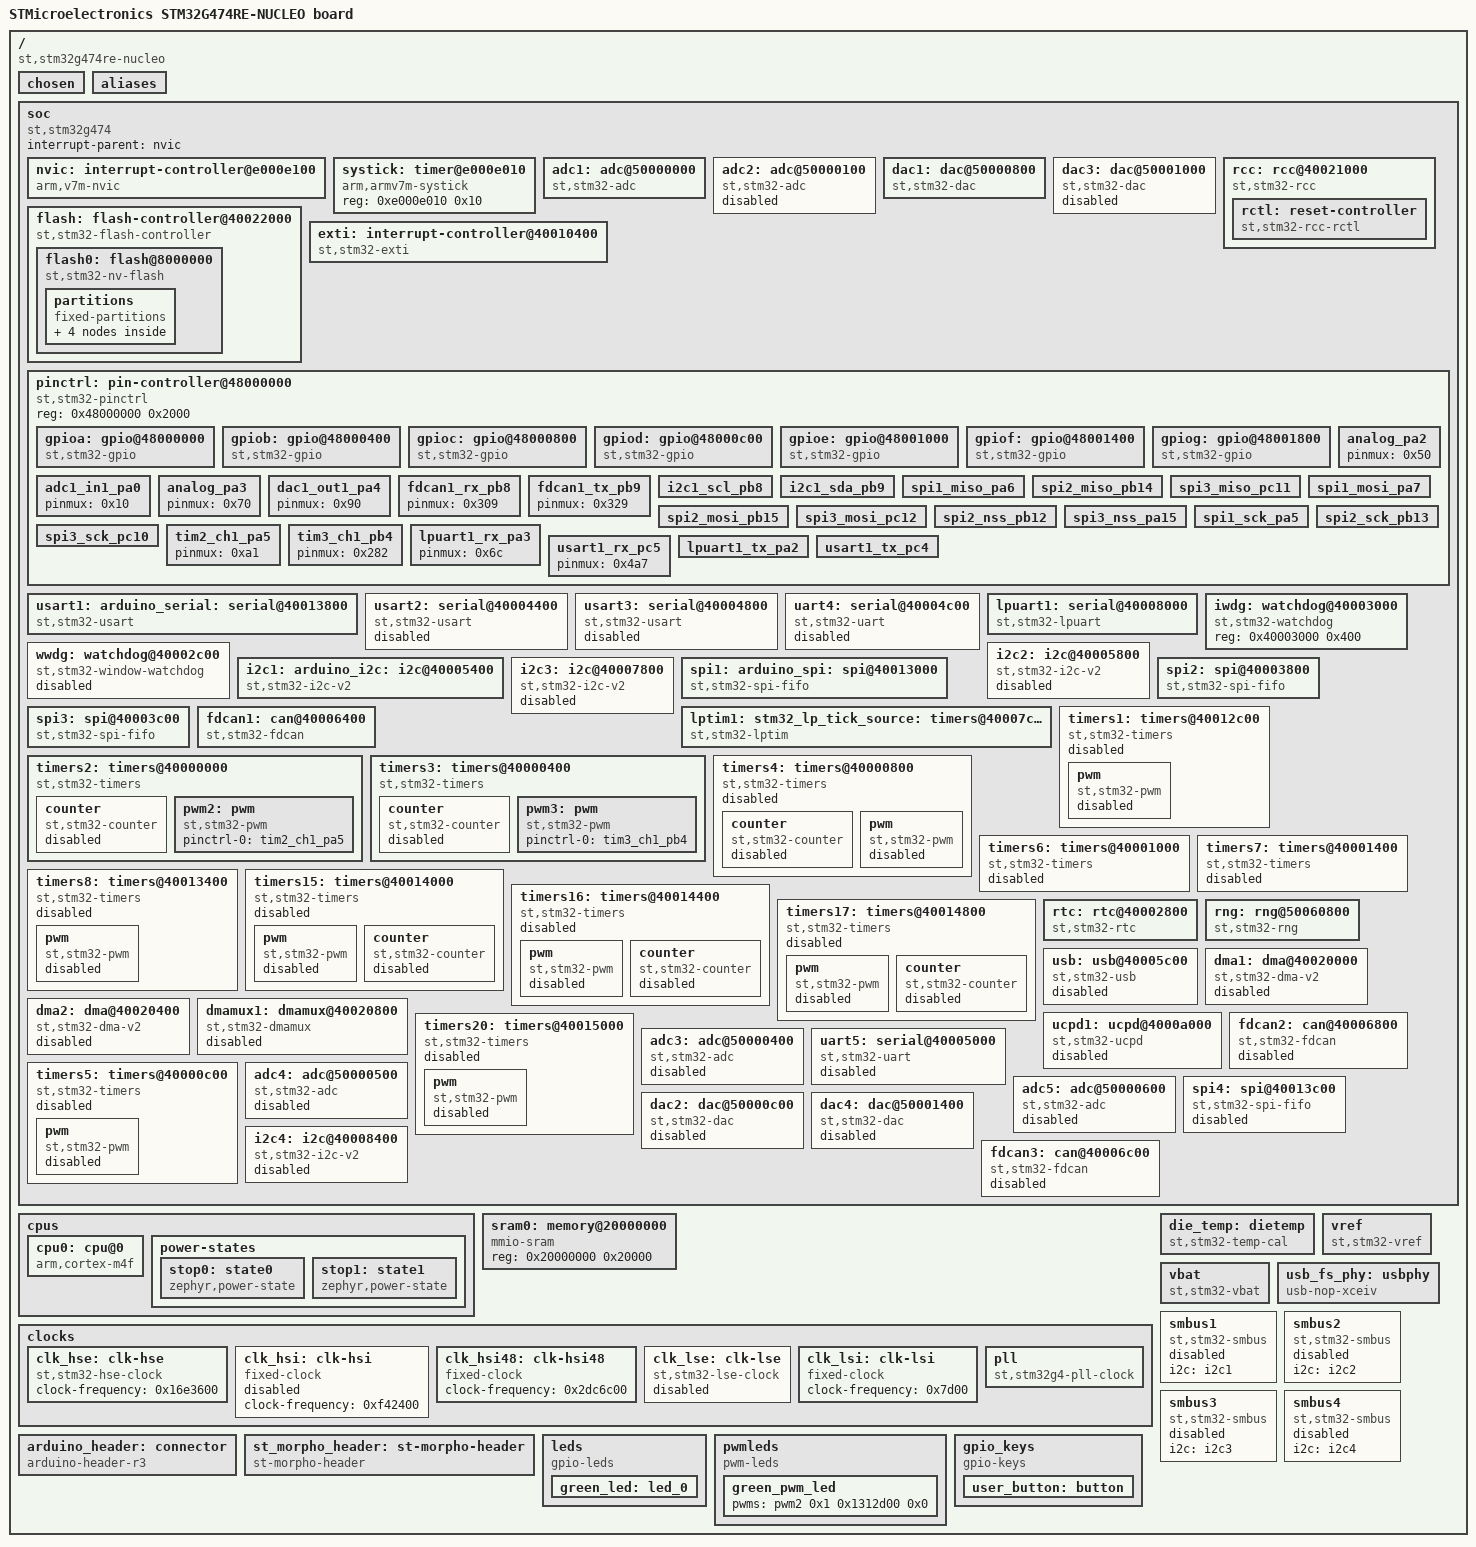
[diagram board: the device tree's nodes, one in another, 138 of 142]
/dts-v1/;

/* node '/' defined in zephyr/dts/common/skeleton.dtsi:9 */
/ {
	#address-cells = < 0x1 >;                              /* in zephyr/dts/common/skeleton.dtsi:10 */
	#size-cells = < 0x1 >;                                 /* in zephyr/dts/common/skeleton.dtsi:11 */
	model = "STMicroelectronics STM32G474RE-NUCLEO board"; /* in zephyr/boards/st/nucleo_g474re/nucleo_g474re.dts:15 */
	compatible = "st,stm32g474re-nucleo";                  /* in zephyr/boards/st/nucleo_g474re/nucleo_g474re.dts:16 */

	/* node '/chosen' defined in zephyr/dts/common/skeleton.dtsi:12 */
	chosen {
		zephyr,entropy = &rng;                    /* in zephyr/dts/arm/st/g4/stm32g4.dtsi:24 */
		zephyr,flash-controller = &flash;         /* in zephyr/dts/arm/st/g4/stm32g4.dtsi:25 */
		zephyr,console = &lpuart1;                /* in zephyr/boards/st/nucleo_g474re/nucleo_g474re.dts:19 */
		zephyr,shell-uart = &lpuart1;             /* in zephyr/boards/st/nucleo_g474re/nucleo_g474re.dts:20 */
		zephyr,sram = &sram0;                     /* in zephyr/boards/st/nucleo_g474re/nucleo_g474re.dts:21 */
		zephyr,flash = &flash0;                   /* in zephyr/boards/st/nucleo_g474re/nucleo_g474re.dts:22 */
		zephyr,code-partition = &slot0_partition; /* in zephyr/boards/st/nucleo_g474re/nucleo_g474re.dts:24 */
		zephyr,canbus = &fdcan1;                  /* in ecu-edge-ai-can-anomaly/firmware/ecu_engine/nucleo_g474re.overlay:19 */
	};

	/* node '/aliases' defined in zephyr/dts/common/skeleton.dtsi:13 */
	aliases {
		led0 = &green_led;         /* in zephyr/boards/st/nucleo_g474re/nucleo_g474re.dts:55 */
		mcuboot-led0 = &green_led; /* in zephyr/boards/st/nucleo_g474re/nucleo_g474re.dts:56 */
		pwm-led0 = &green_pwm_led; /* in zephyr/boards/st/nucleo_g474re/nucleo_g474re.dts:57 */
		sw0 = &user_button;        /* in zephyr/boards/st/nucleo_g474re/nucleo_g474re.dts:58 */
		watchdog0 = &iwdg;         /* in zephyr/boards/st/nucleo_g474re/nucleo_g474re.dts:59 */
		die-temp0 = &die_temp;     /* in zephyr/boards/st/nucleo_g474re/nucleo_g474re.dts:60 */
		volt-sensor0 = &vref;      /* in zephyr/boards/st/nucleo_g474re/nucleo_g474re.dts:61 */
		volt-sensor1 = &vbat;      /* in zephyr/boards/st/nucleo_g474re/nucleo_g474re.dts:62 */
	};

	/* node '/soc' defined in zephyr/dts/arm/armv7-m.dtsi:6 */
	soc {
		#address-cells = < 0x1 >;     /* in zephyr/dts/arm/armv7-m.dtsi:7 */
		#size-cells = < 0x1 >;        /* in zephyr/dts/arm/armv7-m.dtsi:8 */
		interrupt-parent = < &nvic >; /* in zephyr/dts/arm/armv7-m.dtsi:10 */
		ranges;                       /* in zephyr/dts/arm/armv7-m.dtsi:11 */
		compatible = "st,stm32g474",
		             "st,stm32g4",
		             "simple-bus";    /* in zephyr/dts/arm/st/g4/stm32g474.dtsi:11 */

		/* node '/soc/interrupt-controller@e000e100' defined in zephyr/dts/arm/armv7-m.dtsi:13 */
		nvic: interrupt-controller@e000e100 {
			#address-cells = < 0x1 >;            /* in zephyr/dts/arm/armv7-m.dtsi:14 */
			compatible = "arm,v7m-nvic";         /* in zephyr/dts/arm/armv7-m.dtsi:15 */
			reg = < 0xe000e100 0xc00 >;          /* in zephyr/dts/arm/armv7-m.dtsi:16 */
			interrupt-controller;                /* in zephyr/dts/arm/armv7-m.dtsi:17 */
			#interrupt-cells = < 0x2 >;          /* in zephyr/dts/arm/armv7-m.dtsi:18 */
			arm,num-irq-priority-bits = < 0x4 >; /* in zephyr/dts/arm/st/g4/stm32g4.dtsi:726 */
			phandle = < 0x1 >;                   /* in zephyr/dts/arm/armv7-m.dtsi:10 */
		};

		/* node '/soc/timer@e000e010' defined in zephyr/dts/arm/armv7-m.dtsi:21 */
		systick: timer@e000e010 {
			compatible = "arm,armv7m-systick"; /* in zephyr/dts/arm/armv7-m.dtsi:22 */
			reg = < 0xe000e010 0x10 >;         /* in zephyr/dts/arm/armv7-m.dtsi:23 */
		};

		/* node '/soc/adc@50000000' defined in zephyr/dts/arm/st/g4/stm32g4.dtsi:106 */
		adc1: adc@50000000 {
			compatible = "st,stm32-adc";                                /* in zephyr/dts/arm/st/g4/stm32g4.dtsi:107 */
			reg = < 0x50000000 0x100 >;                                 /* in zephyr/dts/arm/st/g4/stm32g4.dtsi:108 */
			clocks = < &rcc 0x4c 0x2000 >;                              /* in zephyr/dts/arm/st/g4/stm32g4.dtsi:109 */
			interrupts = < 0x12 0x0 >;                                  /* in zephyr/dts/arm/st/g4/stm32g4.dtsi:110 */
			#io-channel-cells = < 0x1 >;                                /* in zephyr/dts/arm/st/g4/stm32g4.dtsi:112 */
			resolutions = < 0x60630c 0x51630c 0x42630c 0x33630c >;      /* in zephyr/dts/arm/st/g4/stm32g4.dtsi:113 */
			sampling-times = < 0x3 0x7 0xd 0x19 0x30 0x5d 0xf8 0x281 >; /* in zephyr/dts/arm/st/g4/stm32g4.dtsi:117 */
			st,adc-sequencer = "FULLY_CONFIGURABLE";                    /* in zephyr/dts/arm/st/g4/stm32g4.dtsi:118 */
			st,adc-oversampler = "OVERSAMPLER_MINIMAL";                 /* in zephyr/dts/arm/st/g4/stm32g4.dtsi:119 */
			pinctrl-0 = < &adc1_in1_pa0 >;                              /* in zephyr/boards/st/nucleo_g474re/nucleo_g474re.dts:210 */
			pinctrl-names = "default";                                  /* in zephyr/boards/st/nucleo_g474re/nucleo_g474re.dts:211 */
			st,adc-clock-source = "SYNC";                               /* in zephyr/boards/st/nucleo_g474re/nucleo_g474re.dts:212 */
			st,adc-prescaler = < 0x4 >;                                 /* in zephyr/boards/st/nucleo_g474re/nucleo_g474re.dts:213 */
			status = "okay";                                            /* in zephyr/boards/st/nucleo_g474re/nucleo_g474re.dts:214 */
			phandle = < 0x23 >;                                         /* in zephyr/dts/arm/st/g4/stm32g4.dtsi:676 */
		};

		/* node '/soc/adc@50000100' defined in zephyr/dts/arm/st/g4/stm32g4.dtsi:122 */
		adc2: adc@50000100 {
			compatible = "st,stm32-adc";                                /* in zephyr/dts/arm/st/g4/stm32g4.dtsi:123 */
			reg = < 0x50000100 0x100 >;                                 /* in zephyr/dts/arm/st/g4/stm32g4.dtsi:124 */
			clocks = < &rcc 0x4c 0x2000 >;                              /* in zephyr/dts/arm/st/g4/stm32g4.dtsi:125 */
			interrupts = < 0x12 0x0 >;                                  /* in zephyr/dts/arm/st/g4/stm32g4.dtsi:126 */
			status = "disabled";                                        /* in zephyr/dts/arm/st/g4/stm32g4.dtsi:127 */
			#io-channel-cells = < 0x1 >;                                /* in zephyr/dts/arm/st/g4/stm32g4.dtsi:128 */
			resolutions = < 0x60630c 0x51630c 0x42630c 0x33630c >;      /* in zephyr/dts/arm/st/g4/stm32g4.dtsi:129 */
			sampling-times = < 0x3 0x7 0xd 0x19 0x30 0x5d 0xf8 0x281 >; /* in zephyr/dts/arm/st/g4/stm32g4.dtsi:133 */
			st,adc-sequencer = "FULLY_CONFIGURABLE";                    /* in zephyr/dts/arm/st/g4/stm32g4.dtsi:134 */
			st,adc-oversampler = "OVERSAMPLER_MINIMAL";                 /* in zephyr/dts/arm/st/g4/stm32g4.dtsi:135 */
		};

		/* node '/soc/dac@50000800' defined in zephyr/dts/arm/st/g4/stm32g4.dtsi:138 */
		dac1: dac@50000800 {
			compatible = "st,stm32-dac";    /* in zephyr/dts/arm/st/g4/stm32g4.dtsi:139 */
			reg = < 0x50000800 0x400 >;     /* in zephyr/dts/arm/st/g4/stm32g4.dtsi:140 */
			clocks = < &rcc 0x4c 0x10000 >; /* in zephyr/dts/arm/st/g4/stm32g4.dtsi:141 */
			#io-channel-cells = < 0x1 >;    /* in zephyr/dts/arm/st/g4/stm32g4.dtsi:143 */
			pinctrl-0 = < &dac1_out1_pa4 >; /* in zephyr/boards/st/nucleo_g474re/nucleo_g474re.dts:222 */
			pinctrl-names = "default";      /* in zephyr/boards/st/nucleo_g474re/nucleo_g474re.dts:223 */
			status = "okay";                /* in zephyr/boards/st/nucleo_g474re/nucleo_g474re.dts:224 */
		};

		/* node '/soc/dac@50001000' defined in zephyr/dts/arm/st/g4/stm32g4.dtsi:146 */
		dac3: dac@50001000 {
			compatible = "st,stm32-dac";    /* in zephyr/dts/arm/st/g4/stm32g4.dtsi:147 */
			reg = < 0x50001000 0x400 >;     /* in zephyr/dts/arm/st/g4/stm32g4.dtsi:148 */
			clocks = < &rcc 0x4c 0x40000 >; /* in zephyr/dts/arm/st/g4/stm32g4.dtsi:149 */
			status = "disabled";            /* in zephyr/dts/arm/st/g4/stm32g4.dtsi:150 */
			#io-channel-cells = < 0x1 >;    /* in zephyr/dts/arm/st/g4/stm32g4.dtsi:151 */
		};

		/* node '/soc/flash-controller@40022000' defined in zephyr/dts/arm/st/g4/stm32g4.dtsi:154 */
		flash: flash-controller@40022000 {
			compatible = "st,stm32-flash-controller",
			             "st,stm32g4-flash-controller"; /* in zephyr/dts/arm/st/g4/stm32g4.dtsi:155 */
			reg = < 0x40022000 0x400 >;                 /* in zephyr/dts/arm/st/g4/stm32g4.dtsi:156 */
			interrupts = < 0x3 0x0 >;                   /* in zephyr/dts/arm/st/g4/stm32g4.dtsi:157 */
			clocks = < &rcc 0x48 0x100 >;               /* in zephyr/dts/arm/st/g4/stm32g4.dtsi:158 */
			#address-cells = < 0x1 >;                   /* in zephyr/dts/arm/st/g4/stm32g4.dtsi:160 */
			#size-cells = < 0x1 >;                      /* in zephyr/dts/arm/st/g4/stm32g4.dtsi:161 */

			/* node '/soc/flash-controller@40022000/flash@8000000' defined in zephyr/dts/arm/st/g4/stm32g4.dtsi:163 */
			flash0: flash@8000000 {
				compatible = "st,stm32-nv-flash",
				             "soc-nv-flash";      /* in zephyr/dts/arm/st/g4/stm32g4.dtsi:164 */
				write-block-size = < 0x8 >;       /* in zephyr/dts/arm/st/g4/stm32g4.dtsi:166 */
				erase-block-size = < 0x800 >;     /* in zephyr/dts/arm/st/g4/stm32g4.dtsi:167 */
				max-erase-time = < 0x19 >;        /* in zephyr/dts/arm/st/g4/stm32g4.dtsi:169 */
				reg = < 0x8000000 0x80000 >;      /* in zephyr/dts/arm/st/g4/stm32g474Xe.dtsi:15 */

				/* node '/soc/flash-controller@40022000/flash@8000000/partitions' defined in zephyr/boards/st/nucleo_g474re/nucleo_g474re.dts:173 */
				partitions {
					compatible = "fixed-partitions"; /* in zephyr/boards/st/nucleo_g474re/nucleo_g474re.dts:174 */
					#address-cells = < 0x1 >;        /* in zephyr/boards/st/nucleo_g474re/nucleo_g474re.dts:175 */
					#size-cells = < 0x1 >;           /* in zephyr/boards/st/nucleo_g474re/nucleo_g474re.dts:176 */

					/* node '/soc/flash-controller@40022000/flash@8000000/partitions/partition@0' defined in zephyr/boards/st/nucleo_g474re/nucleo_g474re.dts:178 */
					boot_partition: partition@0 {
						label = "mcuboot";    /* in zephyr/boards/st/nucleo_g474re/nucleo_g474re.dts:179 */
						reg = < 0x0 0x8800 >; /* in zephyr/boards/st/nucleo_g474re/nucleo_g474re.dts:180 */
					};

					/* node '/soc/flash-controller@40022000/flash@8000000/partitions/partition@8800' defined in zephyr/boards/st/nucleo_g474re/nucleo_g474re.dts:183 */
					slot0_partition: partition@8800 {
						label = "image-0";        /* in zephyr/boards/st/nucleo_g474re/nucleo_g474re.dts:184 */
						reg = < 0x8800 0x3c000 >; /* in zephyr/boards/st/nucleo_g474re/nucleo_g474re.dts:185 */
					};

					/* node '/soc/flash-controller@40022000/flash@8000000/partitions/partition@44800' defined in zephyr/boards/st/nucleo_g474re/nucleo_g474re.dts:188 */
					slot1_partition: partition@44800 {
						label = "image-1";         /* in zephyr/boards/st/nucleo_g474re/nucleo_g474re.dts:189 */
						reg = < 0x44800 0x3a800 >; /* in zephyr/boards/st/nucleo_g474re/nucleo_g474re.dts:190 */
					};

					/* node '/soc/flash-controller@40022000/flash@8000000/partitions/partition@7f000' defined in zephyr/boards/st/nucleo_g474re/nucleo_g474re.dts:194 */
					storage_partition: partition@7f000 {
						label = "storage";        /* in zephyr/boards/st/nucleo_g474re/nucleo_g474re.dts:195 */
						reg = < 0x7f000 0x1000 >; /* in zephyr/boards/st/nucleo_g474re/nucleo_g474re.dts:196 */
					};
				};
			};
		};

		/* node '/soc/rcc@40021000' defined in zephyr/dts/arm/st/g4/stm32g4.dtsi:173 */
		rcc: rcc@40021000 {
			compatible = "st,stm32-rcc";     /* in zephyr/dts/arm/st/g4/stm32g4.dtsi:174 */
			#clock-cells = < 0x2 >;          /* in zephyr/dts/arm/st/g4/stm32g4.dtsi:175 */
			reg = < 0x40021000 0x400 >;      /* in zephyr/dts/arm/st/g4/stm32g4.dtsi:176 */
			undershoot-prevention;           /* in zephyr/dts/arm/st/g4/stm32g4.dtsi:177 */
			clocks = < &pll >;               /* in zephyr/boards/st/nucleo_g474re/nucleo_g474re.dts:90 */
			clock-frequency = < 0xa21fe80 >; /* in zephyr/boards/st/nucleo_g474re/nucleo_g474re.dts:91 */
			ahb-prescaler = < 0x1 >;         /* in zephyr/boards/st/nucleo_g474re/nucleo_g474re.dts:92 */
			apb1-prescaler = < 0x1 >;        /* in zephyr/boards/st/nucleo_g474re/nucleo_g474re.dts:93 */
			apb2-prescaler = < 0x1 >;        /* in zephyr/boards/st/nucleo_g474re/nucleo_g474re.dts:94 */
			phandle = < 0x2 >;               /* in zephyr/dts/arm/st/g4/stm32g4.dtsi:109 */

			/* node '/soc/rcc@40021000/reset-controller' defined in zephyr/dts/arm/st/g4/stm32g4.dtsi:179 */
			rctl: reset-controller {
				compatible = "st,stm32-rcc-rctl"; /* in zephyr/dts/arm/st/g4/stm32g4.dtsi:180 */
				#reset-cells = < 0x1 >;           /* in zephyr/dts/arm/st/g4/stm32g4.dtsi:181 */
				phandle = < 0x6 >;                /* in zephyr/dts/arm/st/g4/stm32g4.dtsi:268 */
			};
		};

		/* node '/soc/interrupt-controller@40010400' defined in zephyr/dts/arm/st/g4/stm32g4.dtsi:185 */
		exti: interrupt-controller@40010400 {
			compatible = "st,stm32-exti";  /* in zephyr/dts/arm/st/g4/stm32g4.dtsi:186 */
			interrupt-controller;          /* in zephyr/dts/arm/st/g4/stm32g4.dtsi:187 */
			#interrupt-cells = < 0x1 >;    /* in zephyr/dts/arm/st/g4/stm32g4.dtsi:188 */
			#address-cells = < 0x1 >;      /* in zephyr/dts/arm/st/g4/stm32g4.dtsi:189 */
			reg = < 0x40010400 0x400 >;    /* in zephyr/dts/arm/st/g4/stm32g4.dtsi:190 */
			clocks = < &rcc 0x60 0x1 >;    /* in zephyr/dts/arm/st/g4/stm32g4.dtsi:191 */
			num-lines = < 0x40 >;          /* in zephyr/dts/arm/st/g4/stm32g4.dtsi:192 */
			interrupts = < 0x6 0x0 >,
			             < 0x7 0x0 >,
			             < 0x8 0x0 >,
			             < 0x9 0x0 >,
			             < 0xa 0x0 >,
			             < 0x17 0x0 >,
			             < 0x28 0x0 >;     /* in zephyr/dts/arm/st/g4/stm32g4.dtsi:193 */
			interrupt-names = "line0",
			                  "line1",
			                  "line2-TSC",
			                  "line3",
			                  "line4",
			                  "line5-9",
			                  "line10-15"; /* in zephyr/dts/arm/st/g4/stm32g4.dtsi:195 */
			line-ranges = < 0x0 0x1 >,
			              < 0x1 0x1 >,
			              < 0x2 0x1 >,
			              < 0x3 0x1 >,
			              < 0x4 0x1 >,
			              < 0x5 0x5 >,
			              < 0xa 0x6 >;     /* in zephyr/dts/arm/st/g4/stm32g4.dtsi:197 */
		};

		/* node '/soc/pin-controller@48000000' defined in zephyr/dts/arm/st/g4/stm32g4.dtsi:201 */
		pinctrl: pin-controller@48000000 {
			compatible = "st,stm32-pinctrl"; /* in zephyr/dts/arm/st/g4/stm32g4.dtsi:202 */
			#address-cells = < 0x1 >;        /* in zephyr/dts/arm/st/g4/stm32g4.dtsi:203 */
			#size-cells = < 0x1 >;           /* in zephyr/dts/arm/st/g4/stm32g4.dtsi:204 */
			reg = < 0x48000000 0x2000 >;     /* in zephyr/dts/arm/st/g4/stm32g4.dtsi:205 */

			/* node '/soc/pin-controller@48000000/gpio@48000000' defined in zephyr/dts/arm/st/g4/stm32g4.dtsi:207 */
			gpioa: gpio@48000000 {
				compatible = "st,stm32-gpio"; /* in zephyr/dts/arm/st/g4/stm32g4.dtsi:208 */
				gpio-controller;              /* in zephyr/dts/arm/st/g4/stm32g4.dtsi:209 */
				#gpio-cells = < 0x2 >;        /* in zephyr/dts/arm/st/g4/stm32g4.dtsi:210 */
				reg = < 0x48000000 0x400 >;   /* in zephyr/dts/arm/st/g4/stm32g4.dtsi:211 */
				clocks = < &rcc 0x4c 0x1 >;   /* in zephyr/dts/arm/st/g4/stm32g4.dtsi:212 */
				phandle = < 0x28 >;           /* in zephyr/boards/st/nucleo_g474re/arduino_r3_connector.dtsi:13 */
			};

			/* node '/soc/pin-controller@48000000/gpio@48000400' defined in zephyr/dts/arm/st/g4/stm32g4.dtsi:215 */
			gpiob: gpio@48000400 {
				compatible = "st,stm32-gpio"; /* in zephyr/dts/arm/st/g4/stm32g4.dtsi:216 */
				gpio-controller;              /* in zephyr/dts/arm/st/g4/stm32g4.dtsi:217 */
				#gpio-cells = < 0x2 >;        /* in zephyr/dts/arm/st/g4/stm32g4.dtsi:218 */
				reg = < 0x48000400 0x400 >;   /* in zephyr/dts/arm/st/g4/stm32g4.dtsi:219 */
				clocks = < &rcc 0x4c 0x2 >;   /* in zephyr/dts/arm/st/g4/stm32g4.dtsi:220 */
				phandle = < 0x12 >;           /* in zephyr/boards/st/nucleo_g474re/nucleo_g474re.dts:121 */
			};

			/* node '/soc/pin-controller@48000000/gpio@48000800' defined in zephyr/dts/arm/st/g4/stm32g4.dtsi:223 */
			gpioc: gpio@48000800 {
				compatible = "st,stm32-gpio"; /* in zephyr/dts/arm/st/g4/stm32g4.dtsi:224 */
				gpio-controller;              /* in zephyr/dts/arm/st/g4/stm32g4.dtsi:225 */
				#gpio-cells = < 0x2 >;        /* in zephyr/dts/arm/st/g4/stm32g4.dtsi:226 */
				reg = < 0x48000800 0x400 >;   /* in zephyr/dts/arm/st/g4/stm32g4.dtsi:227 */
				clocks = < &rcc 0x4c 0x4 >;   /* in zephyr/dts/arm/st/g4/stm32g4.dtsi:228 */
				phandle = < 0x29 >;           /* in zephyr/boards/st/nucleo_g474re/arduino_r3_connector.dtsi:13 */
			};

			/* node '/soc/pin-controller@48000000/gpio@48000c00' defined in zephyr/dts/arm/st/g4/stm32g4.dtsi:231 */
			gpiod: gpio@48000c00 {
				compatible = "st,stm32-gpio"; /* in zephyr/dts/arm/st/g4/stm32g4.dtsi:232 */
				gpio-controller;              /* in zephyr/dts/arm/st/g4/stm32g4.dtsi:233 */
				#gpio-cells = < 0x2 >;        /* in zephyr/dts/arm/st/g4/stm32g4.dtsi:234 */
				reg = < 0x48000c00 0x400 >;   /* in zephyr/dts/arm/st/g4/stm32g4.dtsi:235 */
				clocks = < &rcc 0x4c 0x8 >;   /* in zephyr/dts/arm/st/g4/stm32g4.dtsi:236 */
				phandle = < 0x2a >;           /* in zephyr/boards/st/nucleo_g474re/st_morpho_connector.dtsi:15 */
			};

			/* node '/soc/pin-controller@48000000/gpio@48001000' defined in zephyr/dts/arm/st/g4/stm32g4.dtsi:239 */
			gpioe: gpio@48001000 {
				compatible = "st,stm32-gpio"; /* in zephyr/dts/arm/st/g4/stm32g4.dtsi:240 */
				gpio-controller;              /* in zephyr/dts/arm/st/g4/stm32g4.dtsi:241 */
				#gpio-cells = < 0x2 >;        /* in zephyr/dts/arm/st/g4/stm32g4.dtsi:242 */
				reg = < 0x48001000 0x400 >;   /* in zephyr/dts/arm/st/g4/stm32g4.dtsi:243 */
				clocks = < &rcc 0x4c 0x10 >;  /* in zephyr/dts/arm/st/g4/stm32g4.dtsi:244 */
			};

			/* node '/soc/pin-controller@48000000/gpio@48001400' defined in zephyr/dts/arm/st/g4/stm32g4.dtsi:247 */
			gpiof: gpio@48001400 {
				compatible = "st,stm32-gpio"; /* in zephyr/dts/arm/st/g4/stm32g4.dtsi:248 */
				gpio-controller;              /* in zephyr/dts/arm/st/g4/stm32g4.dtsi:249 */
				#gpio-cells = < 0x2 >;        /* in zephyr/dts/arm/st/g4/stm32g4.dtsi:250 */
				reg = < 0x48001400 0x400 >;   /* in zephyr/dts/arm/st/g4/stm32g4.dtsi:251 */
				clocks = < &rcc 0x4c 0x20 >;  /* in zephyr/dts/arm/st/g4/stm32g4.dtsi:252 */
				phandle = < 0x2b >;           /* in zephyr/boards/st/nucleo_g474re/st_morpho_connector.dtsi:15 */
			};

			/* node '/soc/pin-controller@48000000/gpio@48001800' defined in zephyr/dts/arm/st/g4/stm32g4.dtsi:255 */
			gpiog: gpio@48001800 {
				compatible = "st,stm32-gpio"; /* in zephyr/dts/arm/st/g4/stm32g4.dtsi:256 */
				gpio-controller;              /* in zephyr/dts/arm/st/g4/stm32g4.dtsi:257 */
				#gpio-cells = < 0x2 >;        /* in zephyr/dts/arm/st/g4/stm32g4.dtsi:258 */
				reg = < 0x48001800 0x400 >;   /* in zephyr/dts/arm/st/g4/stm32g4.dtsi:259 */
				clocks = < &rcc 0x4c 0x40 >;  /* in zephyr/dts/arm/st/g4/stm32g4.dtsi:260 */
			};

			/* node '/soc/pin-controller@48000000/adc1_in1_pa0' defined in modules/hal/stm32/dts/st/g4/stm32g474r(b-c-e)tx-pinctrl.dtsi:15 */
			adc1_in1_pa0: adc1_in1_pa0 {
				pinmux = < 0x10 >; /* in modules/hal/stm32/dts/st/g4/stm32g474r(b-c-e)tx-pinctrl.dtsi:16 */
				phandle = < 0x3 >; /* in zephyr/boards/st/nucleo_g474re/nucleo_g474re.dts:210 */
			};

			/* node '/soc/pin-controller@48000000/analog_pa2' defined in modules/hal/stm32/dts/st/g4/stm32g474r(b-c-e)tx-pinctrl.dtsi:177 */
			analog_pa2: analog_pa2 {
				pinmux = < 0x50 >; /* in modules/hal/stm32/dts/st/g4/stm32g474r(b-c-e)tx-pinctrl.dtsi:178 */
				phandle = < 0xb >; /* in zephyr/boards/st/nucleo_g474re/nucleo_g474re.dts:106 */
			};

			/* node '/soc/pin-controller@48000000/analog_pa3' defined in modules/hal/stm32/dts/st/g4/stm32g474r(b-c-e)tx-pinctrl.dtsi:181 */
			analog_pa3: analog_pa3 {
				pinmux = < 0x70 >; /* in modules/hal/stm32/dts/st/g4/stm32g474r(b-c-e)tx-pinctrl.dtsi:182 */
				phandle = < 0xc >; /* in zephyr/boards/st/nucleo_g474re/nucleo_g474re.dts:106 */
			};

			/* node '/soc/pin-controller@48000000/dac1_out1_pa4' defined in modules/hal/stm32/dts/st/g4/stm32g474r(b-c-e)tx-pinctrl.dtsi:379 */
			dac1_out1_pa4: dac1_out1_pa4 {
				pinmux = < 0x90 >; /* in modules/hal/stm32/dts/st/g4/stm32g474r(b-c-e)tx-pinctrl.dtsi:380 */
				phandle = < 0x4 >; /* in zephyr/boards/st/nucleo_g474re/nucleo_g474re.dts:222 */
			};

			/* node '/soc/pin-controller@48000000/fdcan1_rx_pb8' defined in modules/hal/stm32/dts/st/g4/stm32g474r(b-c-e)tx-pinctrl.dtsi:397 */
			fdcan1_rx_pb8: fdcan1_rx_pb8 {
				pinmux = < 0x309 >; /* in ecu-edge-ai-can-anomaly/firmware/ecu_engine/nucleo_g474re.overlay:3 */
				phandle = < 0x1b >; /* in ecu-edge-ai-can-anomaly/firmware/ecu_engine/nucleo_g474re.overlay:11 */
			};

			/* node '/soc/pin-controller@48000000/fdcan1_tx_pb9' defined in modules/hal/stm32/dts/st/g4/stm32g474r(b-c-e)tx-pinctrl.dtsi:423 */
			fdcan1_tx_pb9: fdcan1_tx_pb9 {
				pinmux = < 0x329 >; /* in ecu-edge-ai-can-anomaly/firmware/ecu_engine/nucleo_g474re.overlay:6 */
				phandle = < 0x1c >; /* in ecu-edge-ai-can-anomaly/firmware/ecu_engine/nucleo_g474re.overlay:11 */
			};

			/* node '/soc/pin-controller@48000000/i2c1_scl_pb8' defined in modules/hal/stm32/dts/st/g4/stm32g474r(b-c-e)tx-pinctrl.dtsi:571 */
			i2c1_scl_pb8: i2c1_scl_pb8 {
				pinmux = < 0x304 >; /* in modules/hal/stm32/dts/st/g4/stm32g474r(b-c-e)tx-pinctrl.dtsi:572 */
				bias-pull-up;       /* in modules/hal/stm32/dts/st/g4/stm32g474r(b-c-e)tx-pinctrl.dtsi:573 */
				drive-open-drain;   /* in modules/hal/stm32/dts/st/g4/stm32g474r(b-c-e)tx-pinctrl.dtsi:574 */
				phandle = < 0xd >;  /* in zephyr/boards/st/nucleo_g474re/nucleo_g474re.dts:113 */
			};

			/* node '/soc/pin-controller@48000000/i2c1_sda_pb9' defined in modules/hal/stm32/dts/st/g4/stm32g474r(b-c-e)tx-pinctrl.dtsi:627 */
			i2c1_sda_pb9: i2c1_sda_pb9 {
				pinmux = < 0x324 >; /* in modules/hal/stm32/dts/st/g4/stm32g474r(b-c-e)tx-pinctrl.dtsi:628 */
				bias-pull-up;       /* in modules/hal/stm32/dts/st/g4/stm32g474r(b-c-e)tx-pinctrl.dtsi:629 */
				drive-open-drain;   /* in modules/hal/stm32/dts/st/g4/stm32g474r(b-c-e)tx-pinctrl.dtsi:630 */
				phandle = < 0xe >;  /* in zephyr/boards/st/nucleo_g474re/nucleo_g474re.dts:113 */
			};

			/* node '/soc/pin-controller@48000000/spi1_miso_pa6' defined in modules/hal/stm32/dts/st/g4/stm32g474r(b-c-e)tx-pinctrl.dtsi:984 */
			spi1_miso_pa6: spi1_miso_pa6 {
				pinmux = < 0xc5 >;  /* in modules/hal/stm32/dts/st/g4/stm32g474r(b-c-e)tx-pinctrl.dtsi:985 */
				bias-pull-down;     /* in modules/hal/stm32/dts/st/g4/stm32g474r(b-c-e)tx-pinctrl.dtsi:986 */
				phandle = < 0x10 >; /* in zephyr/boards/st/nucleo_g474re/nucleo_g474re.dts:119 */
			};

			/* node '/soc/pin-controller@48000000/spi2_miso_pb14' defined in modules/hal/stm32/dts/st/g4/stm32g474r(b-c-e)tx-pinctrl.dtsi:999 */
			spi2_miso_pb14: spi2_miso_pb14 {
				pinmux = < 0x3c5 >; /* in modules/hal/stm32/dts/st/g4/stm32g474r(b-c-e)tx-pinctrl.dtsi:1000 */
				bias-pull-down;     /* in modules/hal/stm32/dts/st/g4/stm32g474r(b-c-e)tx-pinctrl.dtsi:1001 */
				phandle = < 0x15 >; /* in zephyr/boards/st/nucleo_g474re/nucleo_g474re.dts:126 */
			};

			/* node '/soc/pin-controller@48000000/spi3_miso_pc11' defined in modules/hal/stm32/dts/st/g4/stm32g474r(b-c-e)tx-pinctrl.dtsi:1009 */
			spi3_miso_pc11: spi3_miso_pc11 {
				pinmux = < 0x566 >; /* in modules/hal/stm32/dts/st/g4/stm32g474r(b-c-e)tx-pinctrl.dtsi:1010 */
				bias-pull-down;     /* in modules/hal/stm32/dts/st/g4/stm32g474r(b-c-e)tx-pinctrl.dtsi:1011 */
				phandle = < 0x19 >; /* in zephyr/boards/st/nucleo_g474re/nucleo_g474re.dts:134 */
			};

			/* node '/soc/pin-controller@48000000/spi1_mosi_pa7' defined in modules/hal/stm32/dts/st/g4/stm32g474r(b-c-e)tx-pinctrl.dtsi:1016 */
			spi1_mosi_pa7: spi1_mosi_pa7 {
				pinmux = < 0xe5 >;  /* in modules/hal/stm32/dts/st/g4/stm32g474r(b-c-e)tx-pinctrl.dtsi:1017 */
				bias-pull-down;     /* in modules/hal/stm32/dts/st/g4/stm32g474r(b-c-e)tx-pinctrl.dtsi:1018 */
				phandle = < 0x11 >; /* in zephyr/boards/st/nucleo_g474re/nucleo_g474re.dts:119 */
			};

			/* node '/soc/pin-controller@48000000/spi2_mosi_pb15' defined in modules/hal/stm32/dts/st/g4/stm32g474r(b-c-e)tx-pinctrl.dtsi:1031 */
			spi2_mosi_pb15: spi2_mosi_pb15 {
				pinmux = < 0x3e5 >; /* in modules/hal/stm32/dts/st/g4/stm32g474r(b-c-e)tx-pinctrl.dtsi:1032 */
				bias-pull-down;     /* in modules/hal/stm32/dts/st/g4/stm32g474r(b-c-e)tx-pinctrl.dtsi:1033 */
				phandle = < 0x16 >; /* in zephyr/boards/st/nucleo_g474re/nucleo_g474re.dts:126 */
			};

			/* node '/soc/pin-controller@48000000/spi3_mosi_pc12' defined in modules/hal/stm32/dts/st/g4/stm32g474r(b-c-e)tx-pinctrl.dtsi:1041 */
			spi3_mosi_pc12: spi3_mosi_pc12 {
				pinmux = < 0x586 >; /* in modules/hal/stm32/dts/st/g4/stm32g474r(b-c-e)tx-pinctrl.dtsi:1042 */
				bias-pull-down;     /* in modules/hal/stm32/dts/st/g4/stm32g474r(b-c-e)tx-pinctrl.dtsi:1043 */
				phandle = < 0x1a >; /* in zephyr/boards/st/nucleo_g474re/nucleo_g474re.dts:134 */
			};

			/* node '/soc/pin-controller@48000000/spi2_nss_pb12' defined in modules/hal/stm32/dts/st/g4/stm32g474r(b-c-e)tx-pinctrl.dtsi:1058 */
			spi2_nss_pb12: spi2_nss_pb12 {
				pinmux = < 0x385 >; /* in modules/hal/stm32/dts/st/g4/stm32g474r(b-c-e)tx-pinctrl.dtsi:1059 */
				bias-pull-up;       /* in modules/hal/stm32/dts/st/g4/stm32g474r(b-c-e)tx-pinctrl.dtsi:1060 */
				phandle = < 0x13 >; /* in zephyr/boards/st/nucleo_g474re/nucleo_g474re.dts:126 */
			};

			/* node '/soc/pin-controller@48000000/spi3_nss_pa15' defined in modules/hal/stm32/dts/st/g4/stm32g474r(b-c-e)tx-pinctrl.dtsi:1073 */
			spi3_nss_pa15: spi3_nss_pa15 {
				pinmux = < 0x1e6 >; /* in modules/hal/stm32/dts/st/g4/stm32g474r(b-c-e)tx-pinctrl.dtsi:1074 */
				bias-pull-up;       /* in modules/hal/stm32/dts/st/g4/stm32g474r(b-c-e)tx-pinctrl.dtsi:1075 */
				phandle = < 0x17 >; /* in zephyr/boards/st/nucleo_g474re/nucleo_g474re.dts:134 */
			};

			/* node '/soc/pin-controller@48000000/spi1_sck_pa5' defined in modules/hal/stm32/dts/st/g4/stm32g474r(b-c-e)tx-pinctrl.dtsi:1080 */
			spi1_sck_pa5: spi1_sck_pa5 {
				pinmux = < 0xa5 >;             /* in modules/hal/stm32/dts/st/g4/stm32g474r(b-c-e)tx-pinctrl.dtsi:1081 */
				bias-pull-down;                /* in modules/hal/stm32/dts/st/g4/stm32g474r(b-c-e)tx-pinctrl.dtsi:1082 */
				slew-rate = "very-high-speed"; /* in modules/hal/stm32/dts/st/g4/stm32g474r(b-c-e)tx-pinctrl.dtsi:1083 */
				phandle = < 0xf >;             /* in zephyr/boards/st/nucleo_g474re/nucleo_g474re.dts:119 */
			};

			/* node '/soc/pin-controller@48000000/spi2_sck_pb13' defined in modules/hal/stm32/dts/st/g4/stm32g474r(b-c-e)tx-pinctrl.dtsi:1092 */
			spi2_sck_pb13: spi2_sck_pb13 {
				pinmux = < 0x3a5 >;            /* in modules/hal/stm32/dts/st/g4/stm32g474r(b-c-e)tx-pinctrl.dtsi:1093 */
				bias-pull-down;                /* in modules/hal/stm32/dts/st/g4/stm32g474r(b-c-e)tx-pinctrl.dtsi:1094 */
				slew-rate = "very-high-speed"; /* in modules/hal/stm32/dts/st/g4/stm32g474r(b-c-e)tx-pinctrl.dtsi:1095 */
				phandle = < 0x14 >;            /* in zephyr/boards/st/nucleo_g474re/nucleo_g474re.dts:126 */
			};

			/* node '/soc/pin-controller@48000000/spi3_sck_pc10' defined in modules/hal/stm32/dts/st/g4/stm32g474r(b-c-e)tx-pinctrl.dtsi:1110 */
			spi3_sck_pc10: spi3_sck_pc10 {
				pinmux = < 0x546 >;            /* in modules/hal/stm32/dts/st/g4/stm32g474r(b-c-e)tx-pinctrl.dtsi:1111 */
				bias-pull-down;                /* in modules/hal/stm32/dts/st/g4/stm32g474r(b-c-e)tx-pinctrl.dtsi:1112 */
				slew-rate = "very-high-speed"; /* in modules/hal/stm32/dts/st/g4/stm32g474r(b-c-e)tx-pinctrl.dtsi:1113 */
				phandle = < 0x18 >;            /* in zephyr/boards/st/nucleo_g474re/nucleo_g474re.dts:134 */
			};

			/* node '/soc/pin-controller@48000000/tim2_ch1_pa5' defined in modules/hal/stm32/dts/st/g4/stm32g474r(b-c-e)tx-pinctrl.dtsi:1312 */
			tim2_ch1_pa5: tim2_ch1_pa5 {
				pinmux = < 0xa1 >;  /* in modules/hal/stm32/dts/st/g4/stm32g474r(b-c-e)tx-pinctrl.dtsi:1313 */
				phandle = < 0x1d >; /* in zephyr/boards/st/nucleo_g474re/nucleo_g474re.dts:145 */
			};

			/* node '/soc/pin-controller@48000000/tim3_ch1_pb4' defined in modules/hal/stm32/dts/st/g4/stm32g474r(b-c-e)tx-pinctrl.dtsi:1360 */
			tim3_ch1_pb4: tim3_ch1_pb4 {
				pinmux = < 0x282 >; /* in modules/hal/stm32/dts/st/g4/stm32g474r(b-c-e)tx-pinctrl.dtsi:1361 */
				phandle = < 0x1e >; /* in zephyr/boards/st/nucleo_g474re/nucleo_g474re.dts:155 */
			};

			/* node '/soc/pin-controller@48000000/lpuart1_rx_pa3' defined in modules/hal/stm32/dts/st/g4/stm32g474r(b-c-e)tx-pinctrl.dtsi:1698 */
			lpuart1_rx_pa3: lpuart1_rx_pa3 {
				pinmux = < 0x6c >; /* in modules/hal/stm32/dts/st/g4/stm32g474r(b-c-e)tx-pinctrl.dtsi:1699 */
				phandle = < 0xa >; /* in zephyr/boards/st/nucleo_g474re/nucleo_g474re.dts:105 */
			};

			/* node '/soc/pin-controller@48000000/usart1_rx_pc5' defined in modules/hal/stm32/dts/st/g4/stm32g474r(b-c-e)tx-pinctrl.dtsi:1718 */
			usart1_rx_pc5: usart1_rx_pc5 {
				pinmux = < 0x4a7 >; /* in modules/hal/stm32/dts/st/g4/stm32g474r(b-c-e)tx-pinctrl.dtsi:1719 */
				phandle = < 0x8 >;  /* in zephyr/boards/st/nucleo_g474re/nucleo_g474re.dts:98 */
			};

			/* node '/soc/pin-controller@48000000/lpuart1_tx_pa2' defined in modules/hal/stm32/dts/st/g4/stm32g474r(b-c-e)tx-pinctrl.dtsi:1756 */
			lpuart1_tx_pa2: lpuart1_tx_pa2 {
				pinmux = < 0x4c >; /* in modules/hal/stm32/dts/st/g4/stm32g474r(b-c-e)tx-pinctrl.dtsi:1757 */
				bias-pull-up;      /* in modules/hal/stm32/dts/st/g4/stm32g474r(b-c-e)tx-pinctrl.dtsi:1758 */
				phandle = < 0x9 >; /* in zephyr/boards/st/nucleo_g474re/nucleo_g474re.dts:105 */
			};

			/* node '/soc/pin-controller@48000000/usart1_tx_pc4' defined in modules/hal/stm32/dts/st/g4/stm32g474r(b-c-e)tx-pinctrl.dtsi:1781 */
			usart1_tx_pc4: usart1_tx_pc4 {
				pinmux = < 0x487 >; /* in modules/hal/stm32/dts/st/g4/stm32g474r(b-c-e)tx-pinctrl.dtsi:1782 */
				bias-pull-up;       /* in modules/hal/stm32/dts/st/g4/stm32g474r(b-c-e)tx-pinctrl.dtsi:1783 */
				phandle = < 0x7 >;  /* in zephyr/boards/st/nucleo_g474re/nucleo_g474re.dts:98 */
			};
		};

		/* node '/soc/serial@40013800' defined in zephyr/dts/arm/st/g4/stm32g4.dtsi:264 */
		usart1: arduino_serial: serial@40013800 {
			compatible = "st,stm32-usart",
			             "st,stm32-uart";                  /* in zephyr/dts/arm/st/g4/stm32g4.dtsi:265 */
			reg = < 0x40013800 0x400 >;                    /* in zephyr/dts/arm/st/g4/stm32g4.dtsi:266 */
			clocks = < &rcc 0x60 0x4000 >;                 /* in zephyr/dts/arm/st/g4/stm32g4.dtsi:267 */
			resets = < &rctl 0x80e >;                      /* in zephyr/dts/arm/st/g4/stm32g4.dtsi:268 */
			interrupts = < 0x25 0x0 >;                     /* in zephyr/dts/arm/st/g4/stm32g4.dtsi:269 */
			pinctrl-0 = < &usart1_tx_pc4 &usart1_rx_pc5 >; /* in zephyr/boards/st/nucleo_g474re/nucleo_g474re.dts:98 */
			pinctrl-names = "default";                     /* in zephyr/boards/st/nucleo_g474re/nucleo_g474re.dts:99 */
			current-speed = < 0x1c200 >;                   /* in zephyr/boards/st/nucleo_g474re/nucleo_g474re.dts:100 */
			status = "okay";                               /* in zephyr/boards/st/nucleo_g474re/nucleo_g474re.dts:101 */
		};

		/* node '/soc/serial@40004400' defined in zephyr/dts/arm/st/g4/stm32g4.dtsi:273 */
		usart2: serial@40004400 {
			compatible = "st,stm32-usart",
			             "st,stm32-uart";   /* in zephyr/dts/arm/st/g4/stm32g4.dtsi:274 */
			reg = < 0x40004400 0x400 >;     /* in zephyr/dts/arm/st/g4/stm32g4.dtsi:275 */
			clocks = < &rcc 0x58 0x20000 >; /* in zephyr/dts/arm/st/g4/stm32g4.dtsi:276 */
			resets = < &rctl 0x711 >;       /* in zephyr/dts/arm/st/g4/stm32g4.dtsi:277 */
			interrupts = < 0x26 0x0 >;      /* in zephyr/dts/arm/st/g4/stm32g4.dtsi:278 */
			status = "disabled";            /* in zephyr/dts/arm/st/g4/stm32g4.dtsi:279 */
		};

		/* node '/soc/serial@40004800' defined in zephyr/dts/arm/st/g4/stm32g4.dtsi:282 */
		usart3: serial@40004800 {
			compatible = "st,stm32-usart",
			             "st,stm32-uart";   /* in zephyr/dts/arm/st/g4/stm32g4.dtsi:283 */
			reg = < 0x40004800 0x400 >;     /* in zephyr/dts/arm/st/g4/stm32g4.dtsi:284 */
			clocks = < &rcc 0x58 0x40000 >; /* in zephyr/dts/arm/st/g4/stm32g4.dtsi:285 */
			resets = < &rctl 0x712 >;       /* in zephyr/dts/arm/st/g4/stm32g4.dtsi:286 */
			interrupts = < 0x27 0x0 >;      /* in zephyr/dts/arm/st/g4/stm32g4.dtsi:287 */
			status = "disabled";            /* in zephyr/dts/arm/st/g4/stm32g4.dtsi:288 */
		};

		/* node '/soc/serial@40004c00' defined in zephyr/dts/arm/st/g4/stm32g4.dtsi:291 */
		uart4: serial@40004c00 {
			compatible = "st,stm32-uart";   /* in zephyr/dts/arm/st/g4/stm32g4.dtsi:292 */
			reg = < 0x40004c00 0x400 >;     /* in zephyr/dts/arm/st/g4/stm32g4.dtsi:293 */
			clocks = < &rcc 0x58 0x80000 >; /* in zephyr/dts/arm/st/g4/stm32g4.dtsi:294 */
			resets = < &rctl 0x713 >;       /* in zephyr/dts/arm/st/g4/stm32g4.dtsi:295 */
			interrupts = < 0x34 0x0 >;      /* in zephyr/dts/arm/st/g4/stm32g4.dtsi:296 */
			status = "disabled";            /* in zephyr/dts/arm/st/g4/stm32g4.dtsi:297 */
		};

		/* node '/soc/serial@40008000' defined in zephyr/dts/arm/st/g4/stm32g4.dtsi:300 */
		lpuart1: serial@40008000 {
			compatible = "st,stm32-lpuart",
			             "st,stm32-uart";                    /* in zephyr/dts/arm/st/g4/stm32g4.dtsi:301 */
			reg = < 0x40008000 0x400 >;                      /* in zephyr/dts/arm/st/g4/stm32g4.dtsi:302 */
			clocks = < &rcc 0x5c 0x1 >;                      /* in zephyr/dts/arm/st/g4/stm32g4.dtsi:303 */
			resets = < &rctl 0x780 >;                        /* in zephyr/dts/arm/st/g4/stm32g4.dtsi:304 */
			interrupts = < 0x5b 0x0 >;                       /* in zephyr/dts/arm/st/g4/stm32g4.dtsi:305 */
			pinctrl-0 = < &lpuart1_tx_pa2 &lpuart1_rx_pa3 >; /* in zephyr/boards/st/nucleo_g474re/nucleo_g474re.dts:105 */
			pinctrl-1 = < &analog_pa2 &analog_pa3 >;         /* in zephyr/boards/st/nucleo_g474re/nucleo_g474re.dts:106 */
			pinctrl-names = "default",
			                "sleep";                         /* in zephyr/boards/st/nucleo_g474re/nucleo_g474re.dts:107 */
			current-speed = < 0x1c200 >;                     /* in zephyr/boards/st/nucleo_g474re/nucleo_g474re.dts:108 */
			status = "okay";                                 /* in zephyr/boards/st/nucleo_g474re/nucleo_g474re.dts:109 */
		};

		/* node '/soc/watchdog@40003000' defined in zephyr/dts/arm/st/g4/stm32g4.dtsi:309 */
		iwdg: watchdog@40003000 {
			compatible = "st,stm32-watchdog"; /* in zephyr/dts/arm/st/g4/stm32g4.dtsi:310 */
			reg = < 0x40003000 0x400 >;       /* in zephyr/dts/arm/st/g4/stm32g4.dtsi:311 */
			status = "okay";                  /* in zephyr/boards/st/nucleo_g474re/nucleo_g474re.dts:202 */
		};

		/* node '/soc/watchdog@40002c00' defined in zephyr/dts/arm/st/g4/stm32g4.dtsi:315 */
		wwdg: watchdog@40002c00 {
			compatible = "st,stm32-window-watchdog"; /* in zephyr/dts/arm/st/g4/stm32g4.dtsi:316 */
			reg = < 0x40002c00 0x400 >;              /* in zephyr/dts/arm/st/g4/stm32g4.dtsi:317 */
			clocks = < &rcc 0x58 0x800 >;            /* in zephyr/dts/arm/st/g4/stm32g4.dtsi:318 */
			interrupts = < 0x0 0x7 >;                /* in zephyr/dts/arm/st/g4/stm32g4.dtsi:319 */
			status = "disabled";                     /* in zephyr/dts/arm/st/g4/stm32g4.dtsi:320 */
		};

		/* node '/soc/i2c@40005400' defined in zephyr/dts/arm/st/g4/stm32g4.dtsi:323 */
		i2c1: arduino_i2c: i2c@40005400 {
			compatible = "st,stm32-i2c-v2";              /* in zephyr/dts/arm/st/g4/stm32g4.dtsi:324 */
			clock-frequency = < 0x186a0 >;               /* in zephyr/dts/arm/st/g4/stm32g4.dtsi:325 */
			#address-cells = < 0x1 >;                    /* in zephyr/dts/arm/st/g4/stm32g4.dtsi:326 */
			#size-cells = < 0x0 >;                       /* in zephyr/dts/arm/st/g4/stm32g4.dtsi:327 */
			reg = < 0x40005400 0x400 >;                  /* in zephyr/dts/arm/st/g4/stm32g4.dtsi:328 */
			clocks = < &rcc 0x58 0x200000 >;             /* in zephyr/dts/arm/st/g4/stm32g4.dtsi:329 */
			interrupts = < 0x1f 0x0 >,
			             < 0x20 0x0 >;                   /* in zephyr/dts/arm/st/g4/stm32g4.dtsi:330 */
			interrupt-names = "event",
			                  "error";                   /* in zephyr/dts/arm/st/g4/stm32g4.dtsi:331 */
			pinctrl-0 = < &i2c1_scl_pb8 &i2c1_sda_pb9 >; /* in zephyr/boards/st/nucleo_g474re/nucleo_g474re.dts:113 */
			pinctrl-names = "default";                   /* in zephyr/boards/st/nucleo_g474re/nucleo_g474re.dts:114 */
			status = "okay";                             /* in zephyr/boards/st/nucleo_g474re/nucleo_g474re.dts:115 */
			phandle = < 0x24 >;                          /* in zephyr/dts/arm/st/g4/stm32g4.dtsi:704 */
		};

		/* node '/soc/i2c@40005800' defined in zephyr/dts/arm/st/g4/stm32g4.dtsi:335 */
		i2c2: i2c@40005800 {
			compatible = "st,stm32-i2c-v2";  /* in zephyr/dts/arm/st/g4/stm32g4.dtsi:336 */
			clock-frequency = < 0x186a0 >;   /* in zephyr/dts/arm/st/g4/stm32g4.dtsi:337 */
			#address-cells = < 0x1 >;        /* in zephyr/dts/arm/st/g4/stm32g4.dtsi:338 */
			#size-cells = < 0x0 >;           /* in zephyr/dts/arm/st/g4/stm32g4.dtsi:339 */
			reg = < 0x40005800 0x400 >;      /* in zephyr/dts/arm/st/g4/stm32g4.dtsi:340 */
			clocks = < &rcc 0x58 0x400000 >; /* in zephyr/dts/arm/st/g4/stm32g4.dtsi:341 */
			interrupts = < 0x21 0x0 >,
			             < 0x22 0x0 >;       /* in zephyr/dts/arm/st/g4/stm32g4.dtsi:342 */
			interrupt-names = "event",
			                  "error";       /* in zephyr/dts/arm/st/g4/stm32g4.dtsi:343 */
			status = "disabled";             /* in zephyr/dts/arm/st/g4/stm32g4.dtsi:344 */
			phandle = < 0x25 >;              /* in zephyr/dts/arm/st/g4/stm32g4.dtsi:712 */
		};

		/* node '/soc/i2c@40007800' defined in zephyr/dts/arm/st/g4/stm32g4.dtsi:347 */
		i2c3: i2c@40007800 {
			compatible = "st,stm32-i2c-v2";    /* in zephyr/dts/arm/st/g4/stm32g4.dtsi:348 */
			clock-frequency = < 0x186a0 >;     /* in zephyr/dts/arm/st/g4/stm32g4.dtsi:349 */
			#address-cells = < 0x1 >;          /* in zephyr/dts/arm/st/g4/stm32g4.dtsi:350 */
			#size-cells = < 0x0 >;             /* in zephyr/dts/arm/st/g4/stm32g4.dtsi:351 */
			reg = < 0x40007800 0x400 >;        /* in zephyr/dts/arm/st/g4/stm32g4.dtsi:352 */
			clocks = < &rcc 0x58 0x40000000 >; /* in zephyr/dts/arm/st/g4/stm32g4.dtsi:353 */
			interrupts = < 0x5c 0x0 >,
			             < 0x5d 0x0 >;         /* in zephyr/dts/arm/st/g4/stm32g4.dtsi:354 */
			interrupt-names = "event",
			                  "error";         /* in zephyr/dts/arm/st/g4/stm32g4.dtsi:355 */
			status = "disabled";               /* in zephyr/dts/arm/st/g4/stm32g4.dtsi:356 */
			phandle = < 0x26 >;                /* in zephyr/dts/arm/st/g4/stm32g4.dtsi:720 */
		};

		/* node '/soc/spi@40013000' defined in zephyr/dts/arm/st/g4/stm32g4.dtsi:359 */
		spi1: arduino_spi: spi@40013000 {
			compatible = "st,stm32-spi-fifo",
			             "st,stm32-spi";                                 /* in zephyr/dts/arm/st/g4/stm32g4.dtsi:360 */
			#address-cells = < 0x1 >;                                    /* in zephyr/dts/arm/st/g4/stm32g4.dtsi:361 */
			#size-cells = < 0x0 >;                                       /* in zephyr/dts/arm/st/g4/stm32g4.dtsi:362 */
			reg = < 0x40013000 0x400 >;                                  /* in zephyr/dts/arm/st/g4/stm32g4.dtsi:363 */
			interrupts = < 0x23 0x5 >;                                   /* in zephyr/dts/arm/st/g4/stm32g4.dtsi:364 */
			clocks = < &rcc 0x60 0x1000 >;                               /* in zephyr/dts/arm/st/g4/stm32g4.dtsi:365 */
			pinctrl-0 = < &spi1_sck_pa5 &spi1_miso_pa6 &spi1_mosi_pa7 >; /* in zephyr/boards/st/nucleo_g474re/nucleo_g474re.dts:119 */
			pinctrl-names = "default";                                   /* in zephyr/boards/st/nucleo_g474re/nucleo_g474re.dts:120 */
			cs-gpios = < &gpiob 0x6 0x11 >;                              /* in zephyr/boards/st/nucleo_g474re/nucleo_g474re.dts:121 */
			status = "okay";                                             /* in zephyr/boards/st/nucleo_g474re/nucleo_g474re.dts:122 */
		};

		/* node '/soc/spi@40003800' defined in zephyr/dts/arm/st/g4/stm32g4.dtsi:369 */
		spi2: spi@40003800 {
			compatible = "st,stm32-spi-fifo",
			             "st,stm32-spi";                                                   /* in zephyr/dts/arm/st/g4/stm32g4.dtsi:370 */
			#address-cells = < 0x1 >;                                                      /* in zephyr/dts/arm/st/g4/stm32g4.dtsi:371 */
			#size-cells = < 0x0 >;                                                         /* in zephyr/dts/arm/st/g4/stm32g4.dtsi:372 */
			reg = < 0x40003800 0x400 >;                                                    /* in zephyr/dts/arm/st/g4/stm32g4.dtsi:373 */
			clocks = < &rcc 0x58 0x4000 >;                                                 /* in zephyr/dts/arm/st/g4/stm32g4.dtsi:374 */
			interrupts = < 0x24 0x5 >;                                                     /* in zephyr/dts/arm/st/g4/stm32g4.dtsi:375 */
			pinctrl-0 = < &spi2_nss_pb12 &spi2_sck_pb13 &spi2_miso_pb14 &spi2_mosi_pb15 >; /* in zephyr/boards/st/nucleo_g474re/nucleo_g474re.dts:126 */
			pinctrl-names = "default";                                                     /* in zephyr/boards/st/nucleo_g474re/nucleo_g474re.dts:128 */
			status = "okay";                                                               /* in zephyr/boards/st/nucleo_g474re/nucleo_g474re.dts:129 */
		};

		/* node '/soc/spi@40003c00' defined in zephyr/dts/arm/st/g4/stm32g4.dtsi:379 */
		spi3: spi@40003c00 {
			compatible = "st,stm32-spi-fifo",
			             "st,stm32-spi";                                                   /* in zephyr/dts/arm/st/g4/stm32g4.dtsi:380 */
			#address-cells = < 0x1 >;                                                      /* in zephyr/dts/arm/st/g4/stm32g4.dtsi:381 */
			#size-cells = < 0x0 >;                                                         /* in zephyr/dts/arm/st/g4/stm32g4.dtsi:382 */
			reg = < 0x40003c00 0x400 >;                                                    /* in zephyr/dts/arm/st/g4/stm32g4.dtsi:383 */
			clocks = < &rcc 0x58 0x8000 >;                                                 /* in zephyr/dts/arm/st/g4/stm32g4.dtsi:384 */
			interrupts = < 0x33 0x5 >;                                                     /* in zephyr/dts/arm/st/g4/stm32g4.dtsi:385 */
			pinctrl-0 = < &spi3_nss_pa15 &spi3_sck_pc10 &spi3_miso_pc11 &spi3_mosi_pc12 >; /* in zephyr/boards/st/nucleo_g474re/nucleo_g474re.dts:134 */
			pinctrl-names = "default";                                                     /* in zephyr/boards/st/nucleo_g474re/nucleo_g474re.dts:136 */
			status = "okay";                                                               /* in zephyr/boards/st/nucleo_g474re/nucleo_g474re.dts:137 */
		};

		/* node '/soc/can@40006400' defined in zephyr/dts/arm/st/g4/stm32g4.dtsi:389 */
		fdcan1: can@40006400 {
			compatible = "st,stm32-fdcan";                         /* in zephyr/dts/arm/st/g4/stm32g4.dtsi:390 */
			reg = < 0x40006400 0x400 >,
			      < 0x4000a400 0x350 >;                            /* in zephyr/dts/arm/st/g4/stm32g4.dtsi:391 */
			reg-names = "m_can",
			            "message_ram";                             /* in zephyr/dts/arm/st/g4/stm32g4.dtsi:392 */
			interrupts = < 0x15 0x0 >,
			             < 0x16 0x0 >;                             /* in zephyr/dts/arm/st/g4/stm32g4.dtsi:393 */
			interrupt-names = "int0",
			                  "int1";                              /* in zephyr/dts/arm/st/g4/stm32g4.dtsi:394 */
			bosch,mram-cfg = < 0x0 0x1c 0x8 0x3 0x3 0x0 0x3 0x3 >; /* in zephyr/dts/arm/st/g4/stm32g4.dtsi:396 */
			clocks = < &rcc 0x58 0x2000000 >,
			         < &rcc 0x6 0xd80088 >;                        /* in zephyr/boards/st/nucleo_g474re/nucleo_g474re.dts:228 */
			pinctrl-0 = < &fdcan1_rx_pb8 &fdcan1_tx_pb9 >;         /* in ecu-edge-ai-can-anomaly/firmware/ecu_engine/nucleo_g474re.overlay:11 */
			pinctrl-names = "default";                             /* in ecu-edge-ai-can-anomaly/firmware/ecu_engine/nucleo_g474re.overlay:12 */
			status = "okay";                                       /* in ecu-edge-ai-can-anomaly/firmware/ecu_engine/nucleo_g474re.overlay:13 */
			bus-speed = < 0x7a120 >;                               /* in ecu-edge-ai-can-anomaly/firmware/ecu_engine/nucleo_g474re.overlay:14 */
		};

		/* node '/soc/timers@40007c00' defined in zephyr/dts/arm/st/g4/stm32g4.dtsi:400 */
		lptim1: stm32_lp_tick_source: timers@40007c00 {
			compatible = "st,stm32-lptim";     /* in zephyr/dts/arm/st/g4/stm32g4.dtsi:401 */
			#address-cells = < 0x1 >;          /* in zephyr/dts/arm/st/g4/stm32g4.dtsi:403 */
			#size-cells = < 0x0 >;             /* in zephyr/dts/arm/st/g4/stm32g4.dtsi:404 */
			reg = < 0x40007c00 0x400 >;        /* in zephyr/dts/arm/st/g4/stm32g4.dtsi:405 */
			interrupts = < 0x31 0x1 >;         /* in zephyr/dts/arm/st/g4/stm32g4.dtsi:406 */
			interrupt-names = "wakeup";        /* in zephyr/dts/arm/st/g4/stm32g4.dtsi:407 */
			clocks = < &rcc 0x58 0x80000000 >,
			         < &rcc 0x3 0x8d20088 >;   /* in zephyr/boards/st/nucleo_g474re/nucleo_g474re.dts:161 */
			status = "okay";                   /* in zephyr/boards/st/nucleo_g474re/nucleo_g474re.dts:163 */
		};

		/* node '/soc/timers@40012c00' defined in zephyr/dts/arm/st/g4/stm32g4.dtsi:411 */
		timers1: timers@40012c00 {
			compatible = "st,stm32-timers"; /* in zephyr/dts/arm/st/g4/stm32g4.dtsi:412 */
			reg = < 0x40012c00 0x400 >;     /* in zephyr/dts/arm/st/g4/stm32g4.dtsi:413 */
			clocks = < &rcc 0x60 0x800 >;   /* in zephyr/dts/arm/st/g4/stm32g4.dtsi:414 */
			resets = < &rctl 0x80b >;       /* in zephyr/dts/arm/st/g4/stm32g4.dtsi:415 */
			interrupts = < 0x18 0x0 >,
			             < 0x19 0x0 >,
			             < 0x1a 0x0 >,
			             < 0x1b 0x0 >;      /* in zephyr/dts/arm/st/g4/stm32g4.dtsi:416 */
			interrupt-names = "brk",
			                  "up",
			                  "trgcom",
			                  "cc";         /* in zephyr/dts/arm/st/g4/stm32g4.dtsi:417 */
			st,prescaler = < 0x0 >;         /* in zephyr/dts/arm/st/g4/stm32g4.dtsi:418 */
			status = "disabled";            /* in zephyr/dts/arm/st/g4/stm32g4.dtsi:419 */

			/* node '/soc/timers@40012c00/pwm' defined in zephyr/dts/arm/st/g4/stm32g4.dtsi:421 */
			pwm {
				compatible = "st,stm32-pwm"; /* in zephyr/dts/arm/st/g4/stm32g4.dtsi:422 */
				status = "disabled";         /* in zephyr/dts/arm/st/g4/stm32g4.dtsi:423 */
				#pwm-cells = < 0x3 >;        /* in zephyr/dts/arm/st/g4/stm32g4.dtsi:424 */
			};
		};

		/* node '/soc/timers@40000000' defined in zephyr/dts/arm/st/g4/stm32g4.dtsi:428 */
		timers2: timers@40000000 {
			compatible = "st,stm32-timers"; /* in zephyr/dts/arm/st/g4/stm32g4.dtsi:429 */
			reg = < 0x40000000 0x400 >;     /* in zephyr/dts/arm/st/g4/stm32g4.dtsi:430 */
			clocks = < &rcc 0x58 0x1 >;     /* in zephyr/dts/arm/st/g4/stm32g4.dtsi:431 */
			resets = < &rctl 0x700 >;       /* in zephyr/dts/arm/st/g4/stm32g4.dtsi:432 */
			interrupts = < 0x1c 0x0 >;      /* in zephyr/dts/arm/st/g4/stm32g4.dtsi:433 */
			interrupt-names = "global";     /* in zephyr/dts/arm/st/g4/stm32g4.dtsi:434 */
			st,prescaler = < 0x0 >;         /* in zephyr/dts/arm/st/g4/stm32g4.dtsi:435 */
			status = "okay";                /* in zephyr/boards/st/nucleo_g474re/nucleo_g474re.dts:141 */

			/* node '/soc/timers@40000000/counter' defined in zephyr/dts/arm/st/g4/stm32g4.dtsi:438 */
			counter {
				compatible = "st,stm32-counter"; /* in zephyr/dts/arm/st/g4/stm32g4.dtsi:439 */
				status = "disabled";             /* in zephyr/dts/arm/st/g4/stm32g4.dtsi:440 */
			};

			/* node '/soc/timers@40000000/pwm' defined in zephyr/dts/arm/st/g4/stm32g4.dtsi:443 */
			pwm2: pwm {
				compatible = "st,stm32-pwm";   /* in zephyr/dts/arm/st/g4/stm32g4.dtsi:444 */
				#pwm-cells = < 0x3 >;          /* in zephyr/dts/arm/st/g4/stm32g4.dtsi:446 */
				status = "okay";               /* in zephyr/boards/st/nucleo_g474re/nucleo_g474re.dts:144 */
				pinctrl-0 = < &tim2_ch1_pa5 >; /* in zephyr/boards/st/nucleo_g474re/nucleo_g474re.dts:145 */
				pinctrl-names = "default";     /* in zephyr/boards/st/nucleo_g474re/nucleo_g474re.dts:146 */
				phandle = < 0x2c >;            /* in zephyr/boards/st/nucleo_g474re/nucleo_g474re.dts:40 */
			};
		};

		/* node '/soc/timers@40000400' defined in zephyr/dts/arm/st/g4/stm32g4.dtsi:450 */
		timers3: timers@40000400 {
			compatible = "st,stm32-timers"; /* in zephyr/dts/arm/st/g4/stm32g4.dtsi:451 */
			reg = < 0x40000400 0x400 >;     /* in zephyr/dts/arm/st/g4/stm32g4.dtsi:452 */
			clocks = < &rcc 0x58 0x2 >;     /* in zephyr/dts/arm/st/g4/stm32g4.dtsi:453 */
			resets = < &rctl 0x701 >;       /* in zephyr/dts/arm/st/g4/stm32g4.dtsi:454 */
			interrupts = < 0x1d 0x0 >;      /* in zephyr/dts/arm/st/g4/stm32g4.dtsi:455 */
			interrupt-names = "global";     /* in zephyr/dts/arm/st/g4/stm32g4.dtsi:456 */
			st,prescaler = < 0x2710 >;      /* in zephyr/boards/st/nucleo_g474re/nucleo_g474re.dts:151 */
			status = "okay";                /* in zephyr/boards/st/nucleo_g474re/nucleo_g474re.dts:152 */

			/* node '/soc/timers@40000400/counter' defined in zephyr/dts/arm/st/g4/stm32g4.dtsi:460 */
			counter {
				compatible = "st,stm32-counter"; /* in zephyr/dts/arm/st/g4/stm32g4.dtsi:461 */
				status = "disabled";             /* in zephyr/dts/arm/st/g4/stm32g4.dtsi:462 */
			};

			/* node '/soc/timers@40000400/pwm' defined in zephyr/dts/arm/st/g4/stm32g4.dtsi:465 */
			pwm3: pwm {
				compatible = "st,stm32-pwm";   /* in zephyr/dts/arm/st/g4/stm32g4.dtsi:466 */
				#pwm-cells = < 0x3 >;          /* in zephyr/dts/arm/st/g4/stm32g4.dtsi:468 */
				status = "okay";               /* in zephyr/boards/st/nucleo_g474re/nucleo_g474re.dts:154 */
				pinctrl-0 = < &tim3_ch1_pb4 >; /* in zephyr/boards/st/nucleo_g474re/nucleo_g474re.dts:155 */
				pinctrl-names = "default";     /* in zephyr/boards/st/nucleo_g474re/nucleo_g474re.dts:156 */
			};
		};

		/* node '/soc/timers@40000800' defined in zephyr/dts/arm/st/g4/stm32g4.dtsi:472 */
		timers4: timers@40000800 {
			compatible = "st,stm32-timers"; /* in zephyr/dts/arm/st/g4/stm32g4.dtsi:473 */
			reg = < 0x40000800 0x400 >;     /* in zephyr/dts/arm/st/g4/stm32g4.dtsi:474 */
			clocks = < &rcc 0x58 0x4 >;     /* in zephyr/dts/arm/st/g4/stm32g4.dtsi:475 */
			resets = < &rctl 0x702 >;       /* in zephyr/dts/arm/st/g4/stm32g4.dtsi:476 */
			interrupts = < 0x1e 0x0 >;      /* in zephyr/dts/arm/st/g4/stm32g4.dtsi:477 */
			interrupt-names = "global";     /* in zephyr/dts/arm/st/g4/stm32g4.dtsi:478 */
			st,prescaler = < 0x0 >;         /* in zephyr/dts/arm/st/g4/stm32g4.dtsi:479 */
			status = "disabled";            /* in zephyr/dts/arm/st/g4/stm32g4.dtsi:480 */

			/* node '/soc/timers@40000800/counter' defined in zephyr/dts/arm/st/g4/stm32g4.dtsi:482 */
			counter {
				compatible = "st,stm32-counter"; /* in zephyr/dts/arm/st/g4/stm32g4.dtsi:483 */
				status = "disabled";             /* in zephyr/dts/arm/st/g4/stm32g4.dtsi:484 */
			};

			/* node '/soc/timers@40000800/pwm' defined in zephyr/dts/arm/st/g4/stm32g4.dtsi:487 */
			pwm {
				compatible = "st,stm32-pwm"; /* in zephyr/dts/arm/st/g4/stm32g4.dtsi:488 */
				status = "disabled";         /* in zephyr/dts/arm/st/g4/stm32g4.dtsi:489 */
				#pwm-cells = < 0x3 >;        /* in zephyr/dts/arm/st/g4/stm32g4.dtsi:490 */
			};
		};

		/* node '/soc/timers@40001000' defined in zephyr/dts/arm/st/g4/stm32g4.dtsi:494 */
		timers6: timers@40001000 {
			compatible = "st,stm32-timers"; /* in zephyr/dts/arm/st/g4/stm32g4.dtsi:495 */
			reg = < 0x40001000 0x400 >;     /* in zephyr/dts/arm/st/g4/stm32g4.dtsi:496 */
			clocks = < &rcc 0x58 0x10 >;    /* in zephyr/dts/arm/st/g4/stm32g4.dtsi:497 */
			resets = < &rctl 0x704 >;       /* in zephyr/dts/arm/st/g4/stm32g4.dtsi:498 */
			interrupts = < 0x36 0x0 >;      /* in zephyr/dts/arm/st/g4/stm32g4.dtsi:499 */
			interrupt-names = "global";     /* in zephyr/dts/arm/st/g4/stm32g4.dtsi:500 */
			st,prescaler = < 0x0 >;         /* in zephyr/dts/arm/st/g4/stm32g4.dtsi:501 */
			status = "disabled";            /* in zephyr/dts/arm/st/g4/stm32g4.dtsi:502 */
		};

		/* node '/soc/timers@40001400' defined in zephyr/dts/arm/st/g4/stm32g4.dtsi:505 */
		timers7: timers@40001400 {
			compatible = "st,stm32-timers"; /* in zephyr/dts/arm/st/g4/stm32g4.dtsi:506 */
			reg = < 0x40001400 0x400 >;     /* in zephyr/dts/arm/st/g4/stm32g4.dtsi:507 */
			clocks = < &rcc 0x58 0x20 >;    /* in zephyr/dts/arm/st/g4/stm32g4.dtsi:508 */
			resets = < &rctl 0x705 >;       /* in zephyr/dts/arm/st/g4/stm32g4.dtsi:509 */
			interrupts = < 0x37 0x0 >;      /* in zephyr/dts/arm/st/g4/stm32g4.dtsi:510 */
			interrupt-names = "global";     /* in zephyr/dts/arm/st/g4/stm32g4.dtsi:511 */
			st,prescaler = < 0x0 >;         /* in zephyr/dts/arm/st/g4/stm32g4.dtsi:512 */
			status = "disabled";            /* in zephyr/dts/arm/st/g4/stm32g4.dtsi:513 */
		};

		/* node '/soc/timers@40013400' defined in zephyr/dts/arm/st/g4/stm32g4.dtsi:516 */
		timers8: timers@40013400 {
			compatible = "st,stm32-timers"; /* in zephyr/dts/arm/st/g4/stm32g4.dtsi:517 */
			reg = < 0x40013400 0x400 >;     /* in zephyr/dts/arm/st/g4/stm32g4.dtsi:518 */
			clocks = < &rcc 0x60 0x2000 >;  /* in zephyr/dts/arm/st/g4/stm32g4.dtsi:519 */
			resets = < &rctl 0x80d >;       /* in zephyr/dts/arm/st/g4/stm32g4.dtsi:520 */
			interrupts = < 0x2b 0x0 >,
			             < 0x2c 0x0 >,
			             < 0x2d 0x0 >,
			             < 0x2e 0x0 >;      /* in zephyr/dts/arm/st/g4/stm32g4.dtsi:521 */
			interrupt-names = "brk",
			                  "up",
			                  "trgcom",
			                  "cc";         /* in zephyr/dts/arm/st/g4/stm32g4.dtsi:522 */
			st,prescaler = < 0x0 >;         /* in zephyr/dts/arm/st/g4/stm32g4.dtsi:523 */
			status = "disabled";            /* in zephyr/dts/arm/st/g4/stm32g4.dtsi:524 */

			/* node '/soc/timers@40013400/pwm' defined in zephyr/dts/arm/st/g4/stm32g4.dtsi:526 */
			pwm {
				compatible = "st,stm32-pwm"; /* in zephyr/dts/arm/st/g4/stm32g4.dtsi:527 */
				status = "disabled";         /* in zephyr/dts/arm/st/g4/stm32g4.dtsi:528 */
				#pwm-cells = < 0x3 >;        /* in zephyr/dts/arm/st/g4/stm32g4.dtsi:529 */
			};
		};

		/* node '/soc/timers@40014000' defined in zephyr/dts/arm/st/g4/stm32g4.dtsi:533 */
		timers15: timers@40014000 {
			compatible = "st,stm32-timers"; /* in zephyr/dts/arm/st/g4/stm32g4.dtsi:534 */
			reg = < 0x40014000 0x400 >;     /* in zephyr/dts/arm/st/g4/stm32g4.dtsi:535 */
			clocks = < &rcc 0x60 0x10000 >; /* in zephyr/dts/arm/st/g4/stm32g4.dtsi:536 */
			resets = < &rctl 0x810 >;       /* in zephyr/dts/arm/st/g4/stm32g4.dtsi:537 */
			interrupts = < 0x18 0x0 >;      /* in zephyr/dts/arm/st/g4/stm32g4.dtsi:538 */
			interrupt-names = "global";     /* in zephyr/dts/arm/st/g4/stm32g4.dtsi:539 */
			st,prescaler = < 0x0 >;         /* in zephyr/dts/arm/st/g4/stm32g4.dtsi:540 */
			status = "disabled";            /* in zephyr/dts/arm/st/g4/stm32g4.dtsi:541 */

			/* node '/soc/timers@40014000/pwm' defined in zephyr/dts/arm/st/g4/stm32g4.dtsi:543 */
			pwm {
				compatible = "st,stm32-pwm"; /* in zephyr/dts/arm/st/g4/stm32g4.dtsi:544 */
				status = "disabled";         /* in zephyr/dts/arm/st/g4/stm32g4.dtsi:545 */
				#pwm-cells = < 0x3 >;        /* in zephyr/dts/arm/st/g4/stm32g4.dtsi:546 */
			};

			/* node '/soc/timers@40014000/counter' defined in zephyr/dts/arm/st/g4/stm32g4.dtsi:549 */
			counter {
				compatible = "st,stm32-counter"; /* in zephyr/dts/arm/st/g4/stm32g4.dtsi:550 */
				status = "disabled";             /* in zephyr/dts/arm/st/g4/stm32g4.dtsi:551 */
			};
		};

		/* node '/soc/timers@40014400' defined in zephyr/dts/arm/st/g4/stm32g4.dtsi:555 */
		timers16: timers@40014400 {
			compatible = "st,stm32-timers"; /* in zephyr/dts/arm/st/g4/stm32g4.dtsi:556 */
			reg = < 0x40014400 0x400 >;     /* in zephyr/dts/arm/st/g4/stm32g4.dtsi:557 */
			clocks = < &rcc 0x60 0x20000 >; /* in zephyr/dts/arm/st/g4/stm32g4.dtsi:558 */
			resets = < &rctl 0x811 >;       /* in zephyr/dts/arm/st/g4/stm32g4.dtsi:559 */
			interrupts = < 0x19 0x0 >;      /* in zephyr/dts/arm/st/g4/stm32g4.dtsi:560 */
			interrupt-names = "global";     /* in zephyr/dts/arm/st/g4/stm32g4.dtsi:561 */
			st,prescaler = < 0x0 >;         /* in zephyr/dts/arm/st/g4/stm32g4.dtsi:562 */
			status = "disabled";            /* in zephyr/dts/arm/st/g4/stm32g4.dtsi:563 */

			/* node '/soc/timers@40014400/pwm' defined in zephyr/dts/arm/st/g4/stm32g4.dtsi:565 */
			pwm {
				compatible = "st,stm32-pwm"; /* in zephyr/dts/arm/st/g4/stm32g4.dtsi:566 */
				status = "disabled";         /* in zephyr/dts/arm/st/g4/stm32g4.dtsi:567 */
				#pwm-cells = < 0x3 >;        /* in zephyr/dts/arm/st/g4/stm32g4.dtsi:568 */
			};

			/* node '/soc/timers@40014400/counter' defined in zephyr/dts/arm/st/g4/stm32g4.dtsi:571 */
			counter {
				compatible = "st,stm32-counter"; /* in zephyr/dts/arm/st/g4/stm32g4.dtsi:572 */
				status = "disabled";             /* in zephyr/dts/arm/st/g4/stm32g4.dtsi:573 */
			};
		};

		/* node '/soc/timers@40014800' defined in zephyr/dts/arm/st/g4/stm32g4.dtsi:577 */
		timers17: timers@40014800 {
			compatible = "st,stm32-timers"; /* in zephyr/dts/arm/st/g4/stm32g4.dtsi:578 */
			reg = < 0x40014800 0x400 >;     /* in zephyr/dts/arm/st/g4/stm32g4.dtsi:579 */
			clocks = < &rcc 0x60 0x40000 >; /* in zephyr/dts/arm/st/g4/stm32g4.dtsi:580 */
			resets = < &rctl 0x812 >;       /* in zephyr/dts/arm/st/g4/stm32g4.dtsi:581 */
			interrupts = < 0x1a 0x0 >;      /* in zephyr/dts/arm/st/g4/stm32g4.dtsi:582 */
			interrupt-names = "global";     /* in zephyr/dts/arm/st/g4/stm32g4.dtsi:583 */
			st,prescaler = < 0x0 >;         /* in zephyr/dts/arm/st/g4/stm32g4.dtsi:584 */
			status = "disabled";            /* in zephyr/dts/arm/st/g4/stm32g4.dtsi:585 */

			/* node '/soc/timers@40014800/pwm' defined in zephyr/dts/arm/st/g4/stm32g4.dtsi:587 */
			pwm {
				compatible = "st,stm32-pwm"; /* in zephyr/dts/arm/st/g4/stm32g4.dtsi:588 */
				status = "disabled";         /* in zephyr/dts/arm/st/g4/stm32g4.dtsi:589 */
				#pwm-cells = < 0x3 >;        /* in zephyr/dts/arm/st/g4/stm32g4.dtsi:590 */
			};

			/* node '/soc/timers@40014800/counter' defined in zephyr/dts/arm/st/g4/stm32g4.dtsi:593 */
			counter {
				compatible = "st,stm32-counter"; /* in zephyr/dts/arm/st/g4/stm32g4.dtsi:594 */
				status = "disabled";             /* in zephyr/dts/arm/st/g4/stm32g4.dtsi:595 */
			};
		};

		/* node '/soc/rtc@40002800' defined in zephyr/dts/arm/st/g4/stm32g4.dtsi:599 */
		rtc: rtc@40002800 {
			compatible = "st,stm32-rtc";      /* in zephyr/dts/arm/st/g4/stm32g4.dtsi:600 */
			reg = < 0x40002800 0x400 >;       /* in zephyr/dts/arm/st/g4/stm32g4.dtsi:601 */
			interrupts = < 0x29 0x0 >;        /* in zephyr/dts/arm/st/g4/stm32g4.dtsi:602 */
			prescaler = < 0x8000 >;           /* in zephyr/dts/arm/st/g4/stm32g4.dtsi:604 */
			alarms-count = < 0x2 >;           /* in zephyr/dts/arm/st/g4/stm32g4.dtsi:605 */
			alrm-exti-line = < 0x11 >;        /* in zephyr/dts/arm/st/g4/stm32g4.dtsi:606 */
			clocks = < &rcc 0x58 0x400 >,
			         < &rcc 0x3 0x10c80090 >; /* in zephyr/boards/st/nucleo_g474re/nucleo_g474re.dts:167 */
			status = "okay";                  /* in zephyr/boards/st/nucleo_g474re/nucleo_g474re.dts:169 */
		};

		/* node '/soc/rng@50060800' defined in zephyr/dts/arm/st/g4/stm32g4.dtsi:610 */
		rng: rng@50060800 {
			compatible = "st,stm32-rng";      /* in zephyr/dts/arm/st/g4/stm32g4.dtsi:611 */
			reg = < 0x50060800 0x400 >;       /* in zephyr/dts/arm/st/g4/stm32g4.dtsi:612 */
			interrupts = < 0x5a 0x0 >;        /* in zephyr/dts/arm/st/g4/stm32g4.dtsi:613 */
			clocks = < &rcc 0x4c 0x4000000 >; /* in zephyr/dts/arm/st/g4/stm32g4.dtsi:614 */
			status = "okay";                  /* in zephyr/boards/st/nucleo_g474re/nucleo_g474re.dts:206 */
		};

		/* node '/soc/usb@40005c00' defined in zephyr/dts/arm/st/g4/stm32g4.dtsi:618 */
		usb: usb@40005c00 {
			compatible = "st,stm32-usb";     /* in zephyr/dts/arm/st/g4/stm32g4.dtsi:619 */
			reg = < 0x40005c00 0x400 >;      /* in zephyr/dts/arm/st/g4/stm32g4.dtsi:620 */
			interrupts = < 0x14 0x0 >,
			             < 0x13 0x0 >;       /* in zephyr/dts/arm/st/g4/stm32g4.dtsi:621 */
			interrupt-names = "usb",
			                  "usbhp";       /* in zephyr/dts/arm/st/g4/stm32g4.dtsi:622 */
			num-bidir-endpoints = < 0x8 >;   /* in zephyr/dts/arm/st/g4/stm32g4.dtsi:623 */
			ram-size = < 0x400 >;            /* in zephyr/dts/arm/st/g4/stm32g4.dtsi:624 */
			maximum-speed = "full-speed";    /* in zephyr/dts/arm/st/g4/stm32g4.dtsi:625 */
			phys = < &usb_fs_phy >;          /* in zephyr/dts/arm/st/g4/stm32g4.dtsi:626 */
			clocks = < &rcc 0x58 0x800000 >,
			         < &rcc 0x5 0xda0088 >;  /* in zephyr/dts/arm/st/g4/stm32g4.dtsi:627 */
			status = "disabled";             /* in zephyr/dts/arm/st/g4/stm32g4.dtsi:629 */
		};

		/* node '/soc/dma@40020000' defined in zephyr/dts/arm/st/g4/stm32g4.dtsi:632 */
		dma1: dma@40020000 {
			compatible = "st,stm32-dma-v2";                                                      /* in zephyr/dts/arm/st/g4/stm32g4.dtsi:633 */
			#dma-cells = < 0x3 >;                                                                /* in zephyr/dts/arm/st/g4/stm32g4.dtsi:634 */
			reg = < 0x40020000 0x400 >;                                                          /* in zephyr/dts/arm/st/g4/stm32g4.dtsi:635 */
			clocks = < &rcc 0x48 0x1 >;                                                          /* in zephyr/dts/arm/st/g4/stm32g4.dtsi:636 */
			dma-offset = < 0x0 >;                                                                /* in zephyr/dts/arm/st/g4/stm32g4.dtsi:637 */
			status = "disabled";                                                                 /* in zephyr/dts/arm/st/g4/stm32g4.dtsi:638 */
			interrupts = < 0xb 0x0 0xc 0x0 0xd 0x0 0xe 0x0 0xf 0x0 0x10 0x0 0x11 0x0 0x60 0x0 >; /* in zephyr/dts/arm/st/g4/stm32g491.dtsi:42 */
			dma-requests = < 0x8 >;                                                              /* in zephyr/dts/arm/st/g4/stm32g491.dtsi:43 */
		};

		/* node '/soc/dma@40020400' defined in zephyr/dts/arm/st/g4/stm32g4.dtsi:641 */
		dma2: dma@40020400 {
			compatible = "st,stm32-dma-v2";                                                           /* in zephyr/dts/arm/st/g4/stm32g4.dtsi:642 */
			#dma-cells = < 0x3 >;                                                                     /* in zephyr/dts/arm/st/g4/stm32g4.dtsi:643 */
			reg = < 0x40020400 0x400 >;                                                               /* in zephyr/dts/arm/st/g4/stm32g4.dtsi:644 */
			clocks = < &rcc 0x48 0x2 >;                                                               /* in zephyr/dts/arm/st/g4/stm32g4.dtsi:645 */
			status = "disabled";                                                                      /* in zephyr/dts/arm/st/g4/stm32g4.dtsi:646 */
			interrupts = < 0x38 0x0 0x39 0x0 0x3a 0x0 0x3b 0x0 0x3c 0x0 0x61 0x0 0x62 0x0 0x63 0x0 >; /* in zephyr/dts/arm/st/g4/stm32g491.dtsi:47 */
			dma-requests = < 0x8 >;                                                                   /* in zephyr/dts/arm/st/g4/stm32g491.dtsi:48 */
			dma-offset = < 0x8 >;                                                                     /* in zephyr/dts/arm/st/g4/stm32g491.dtsi:49 */
		};

		/* node '/soc/dmamux@40020800' defined in zephyr/dts/arm/st/g4/stm32g4.dtsi:649 */
		dmamux1: dmamux@40020800 {
			compatible = "st,stm32-dmamux"; /* in zephyr/dts/arm/st/g4/stm32g4.dtsi:650 */
			#dma-cells = < 0x3 >;           /* in zephyr/dts/arm/st/g4/stm32g4.dtsi:651 */
			reg = < 0x40020800 0x400 >;     /* in zephyr/dts/arm/st/g4/stm32g4.dtsi:652 */
			interrupts = < 0x5e 0x0 >;      /* in zephyr/dts/arm/st/g4/stm32g4.dtsi:653 */
			clocks = < &rcc 0x48 0x4 >;     /* in zephyr/dts/arm/st/g4/stm32g4.dtsi:654 */
			dma-generators = < 0x4 >;       /* in zephyr/dts/arm/st/g4/stm32g4.dtsi:655 */
			dma-requests = < 0x6f >;        /* in zephyr/dts/arm/st/g4/stm32g4.dtsi:656 */
			status = "disabled";            /* in zephyr/dts/arm/st/g4/stm32g4.dtsi:657 */
			dma-channels = < 0x10 >;        /* in zephyr/dts/arm/st/g4/stm32g491.dtsi:53 */
		};

		/* node '/soc/ucpd@4000a000' defined in zephyr/dts/arm/st/g4/stm32g4.dtsi:660 */
		ucpd1: ucpd@4000a000 {
			compatible = "st,stm32-ucpd"; /* in zephyr/dts/arm/st/g4/stm32g4.dtsi:661 */
			reg = < 0x4000a000 0x400 >;   /* in zephyr/dts/arm/st/g4/stm32g4.dtsi:662 */
			clocks = < &rcc 0x58 0x10 >;  /* in zephyr/dts/arm/st/g4/stm32g4.dtsi:663 */
			interrupts = < 0x3f 0x0 >;    /* in zephyr/dts/arm/st/g4/stm32g4.dtsi:664 */
			status = "disabled";          /* in zephyr/dts/arm/st/g4/stm32g4.dtsi:665 */
		};

		/* node '/soc/can@40006800' defined in zephyr/dts/arm/st/g4/stm32g491.dtsi:13 */
		fdcan2: can@40006800 {
			compatible = "st,stm32-fdcan";                           /* in zephyr/dts/arm/st/g4/stm32g491.dtsi:14 */
			reg = < 0x40006800 0x400 >,
			      < 0x4000a400 0x6a0 >;                              /* in zephyr/dts/arm/st/g4/stm32g491.dtsi:15 */
			reg-names = "m_can",
			            "message_ram";                               /* in zephyr/dts/arm/st/g4/stm32g491.dtsi:16 */
			interrupts = < 0x56 0x0 >,
			             < 0x57 0x0 >;                               /* in zephyr/dts/arm/st/g4/stm32g491.dtsi:17 */
			interrupt-names = "int0",
			                  "int1";                                /* in zephyr/dts/arm/st/g4/stm32g491.dtsi:18 */
			clocks = < &rcc 0x58 0x2000000 >;                        /* in zephyr/dts/arm/st/g4/stm32g491.dtsi:19 */
			bosch,mram-cfg = < 0x350 0x1c 0x8 0x3 0x3 0x0 0x3 0x3 >; /* in zephyr/dts/arm/st/g4/stm32g491.dtsi:20 */
			status = "disabled";                                     /* in zephyr/dts/arm/st/g4/stm32g491.dtsi:21 */
		};

		/* node '/soc/timers@40015000' defined in zephyr/dts/arm/st/g4/stm32g491.dtsi:24 */
		timers20: timers@40015000 {
			compatible = "st,stm32-timers";  /* in zephyr/dts/arm/st/g4/stm32g491.dtsi:25 */
			reg = < 0x40015000 0x400 >;      /* in zephyr/dts/arm/st/g4/stm32g491.dtsi:26 */
			clocks = < &rcc 0x60 0x100000 >; /* in zephyr/dts/arm/st/g4/stm32g491.dtsi:27 */
			resets = < &rctl 0x814 >;        /* in zephyr/dts/arm/st/g4/stm32g491.dtsi:28 */
			interrupts = < 0x4d 0x0 >,
			             < 0x4e 0x0 >,
			             < 0x4f 0x0 >,
			             < 0x50 0x0 >;       /* in zephyr/dts/arm/st/g4/stm32g491.dtsi:29 */
			interrupt-names = "brk",
			                  "up",
			                  "trgcom",
			                  "cc";          /* in zephyr/dts/arm/st/g4/stm32g491.dtsi:30 */
			st,prescaler = < 0x0 >;          /* in zephyr/dts/arm/st/g4/stm32g491.dtsi:31 */
			status = "disabled";             /* in zephyr/dts/arm/st/g4/stm32g491.dtsi:32 */

			/* node '/soc/timers@40015000/pwm' defined in zephyr/dts/arm/st/g4/stm32g491.dtsi:34 */
			pwm {
				compatible = "st,stm32-pwm"; /* in zephyr/dts/arm/st/g4/stm32g491.dtsi:35 */
				status = "disabled";         /* in zephyr/dts/arm/st/g4/stm32g491.dtsi:36 */
				#pwm-cells = < 0x3 >;        /* in zephyr/dts/arm/st/g4/stm32g491.dtsi:37 */
			};
		};

		/* node '/soc/adc@50000400' defined in zephyr/dts/arm/st/g4/stm32g491.dtsi:56 */
		adc3: adc@50000400 {
			compatible = "st,stm32-adc";                                /* in zephyr/dts/arm/st/g4/stm32g491.dtsi:57 */
			reg = < 0x50000400 0x100 >;                                 /* in zephyr/dts/arm/st/g4/stm32g491.dtsi:58 */
			clocks = < &rcc 0x4c 0x4000 >;                              /* in zephyr/dts/arm/st/g4/stm32g491.dtsi:59 */
			interrupts = < 0x2f 0x0 >;                                  /* in zephyr/dts/arm/st/g4/stm32g491.dtsi:60 */
			status = "disabled";                                        /* in zephyr/dts/arm/st/g4/stm32g491.dtsi:61 */
			#io-channel-cells = < 0x1 >;                                /* in zephyr/dts/arm/st/g4/stm32g491.dtsi:62 */
			resolutions = < 0x60630c 0x51630c 0x42630c 0x33630c >;      /* in zephyr/dts/arm/st/g4/stm32g491.dtsi:63 */
			sampling-times = < 0x3 0x7 0xd 0x19 0x30 0x5d 0xf8 0x281 >; /* in zephyr/dts/arm/st/g4/stm32g491.dtsi:67 */
			st,adc-sequencer = "FULLY_CONFIGURABLE";                    /* in zephyr/dts/arm/st/g4/stm32g491.dtsi:68 */
			st,adc-oversampler = "OVERSAMPLER_MINIMAL";                 /* in zephyr/dts/arm/st/g4/stm32g491.dtsi:69 */
		};

		/* node '/soc/serial@40005000' defined in zephyr/dts/arm/st/g4/stm32g491.dtsi:72 */
		uart5: serial@40005000 {
			compatible = "st,stm32-uart";    /* in zephyr/dts/arm/st/g4/stm32g491.dtsi:73 */
			reg = < 0x40005000 0x400 >;      /* in zephyr/dts/arm/st/g4/stm32g491.dtsi:74 */
			clocks = < &rcc 0x58 0x100000 >; /* in zephyr/dts/arm/st/g4/stm32g491.dtsi:75 */
			resets = < &rctl 0x714 >;        /* in zephyr/dts/arm/st/g4/stm32g491.dtsi:76 */
			interrupts = < 0x35 0x0 >;       /* in zephyr/dts/arm/st/g4/stm32g491.dtsi:77 */
			status = "disabled";             /* in zephyr/dts/arm/st/g4/stm32g491.dtsi:78 */
		};

		/* node '/soc/timers@40000c00' defined in zephyr/dts/arm/st/g4/stm32g473.dtsi:13 */
		timers5: timers@40000c00 {
			compatible = "st,stm32-timers"; /* in zephyr/dts/arm/st/g4/stm32g473.dtsi:14 */
			reg = < 0x40000c00 0x400 >;     /* in zephyr/dts/arm/st/g4/stm32g473.dtsi:15 */
			clocks = < &rcc 0x58 0x8 >;     /* in zephyr/dts/arm/st/g4/stm32g473.dtsi:16 */
			resets = < &rctl 0x703 >;       /* in zephyr/dts/arm/st/g4/stm32g473.dtsi:17 */
			interrupts = < 0x32 0x0 >;      /* in zephyr/dts/arm/st/g4/stm32g473.dtsi:18 */
			interrupt-names = "global";     /* in zephyr/dts/arm/st/g4/stm32g473.dtsi:19 */
			st,prescaler = < 0x0 >;         /* in zephyr/dts/arm/st/g4/stm32g473.dtsi:20 */
			status = "disabled";            /* in zephyr/dts/arm/st/g4/stm32g473.dtsi:21 */

			/* node '/soc/timers@40000c00/pwm' defined in zephyr/dts/arm/st/g4/stm32g473.dtsi:23 */
			pwm {
				compatible = "st,stm32-pwm"; /* in zephyr/dts/arm/st/g4/stm32g473.dtsi:24 */
				status = "disabled";         /* in zephyr/dts/arm/st/g4/stm32g473.dtsi:25 */
				#pwm-cells = < 0x3 >;        /* in zephyr/dts/arm/st/g4/stm32g473.dtsi:26 */
			};
		};

		/* node '/soc/adc@50000500' defined in zephyr/dts/arm/st/g4/stm32g473.dtsi:30 */
		adc4: adc@50000500 {
			compatible = "st,stm32-adc";                                /* in zephyr/dts/arm/st/g4/stm32g473.dtsi:31 */
			reg = < 0x50000500 0x100 >;                                 /* in zephyr/dts/arm/st/g4/stm32g473.dtsi:32 */
			clocks = < &rcc 0x4c 0x4000 >;                              /* in zephyr/dts/arm/st/g4/stm32g473.dtsi:33 */
			interrupts = < 0x3d 0x0 >;                                  /* in zephyr/dts/arm/st/g4/stm32g473.dtsi:34 */
			status = "disabled";                                        /* in zephyr/dts/arm/st/g4/stm32g473.dtsi:35 */
			#io-channel-cells = < 0x1 >;                                /* in zephyr/dts/arm/st/g4/stm32g473.dtsi:36 */
			resolutions = < 0x60630c 0x51630c 0x42630c 0x33630c >;      /* in zephyr/dts/arm/st/g4/stm32g473.dtsi:37 */
			sampling-times = < 0x3 0x7 0xd 0x19 0x30 0x5d 0xf8 0x281 >; /* in zephyr/dts/arm/st/g4/stm32g473.dtsi:41 */
			st,adc-sequencer = "FULLY_CONFIGURABLE";                    /* in zephyr/dts/arm/st/g4/stm32g473.dtsi:42 */
			st,adc-oversampler = "OVERSAMPLER_MINIMAL";                 /* in zephyr/dts/arm/st/g4/stm32g473.dtsi:43 */
		};

		/* node '/soc/adc@50000600' defined in zephyr/dts/arm/st/g4/stm32g473.dtsi:46 */
		adc5: adc@50000600 {
			compatible = "st,stm32-adc";                                /* in zephyr/dts/arm/st/g4/stm32g473.dtsi:47 */
			reg = < 0x50000600 0x100 >;                                 /* in zephyr/dts/arm/st/g4/stm32g473.dtsi:48 */
			clocks = < &rcc 0x4c 0x4000 >;                              /* in zephyr/dts/arm/st/g4/stm32g473.dtsi:49 */
			interrupts = < 0x3e 0x0 >;                                  /* in zephyr/dts/arm/st/g4/stm32g473.dtsi:50 */
			status = "disabled";                                        /* in zephyr/dts/arm/st/g4/stm32g473.dtsi:51 */
			#io-channel-cells = < 0x1 >;                                /* in zephyr/dts/arm/st/g4/stm32g473.dtsi:52 */
			resolutions = < 0x60630c 0x51630c 0x42630c 0x33630c >;      /* in zephyr/dts/arm/st/g4/stm32g473.dtsi:53 */
			sampling-times = < 0x3 0x7 0xd 0x19 0x30 0x5d 0xf8 0x281 >; /* in zephyr/dts/arm/st/g4/stm32g473.dtsi:57 */
			st,adc-sequencer = "FULLY_CONFIGURABLE";                    /* in zephyr/dts/arm/st/g4/stm32g473.dtsi:58 */
			st,adc-oversampler = "OVERSAMPLER_MINIMAL";                 /* in zephyr/dts/arm/st/g4/stm32g473.dtsi:59 */
		};

		/* node '/soc/spi@40013c00' defined in zephyr/dts/arm/st/g4/stm32g473.dtsi:62 */
		spi4: spi@40013c00 {
			compatible = "st,stm32-spi-fifo",
			             "st,stm32-spi";      /* in zephyr/dts/arm/st/g4/stm32g473.dtsi:63 */
			#address-cells = < 0x1 >;         /* in zephyr/dts/arm/st/g4/stm32g473.dtsi:64 */
			#size-cells = < 0x0 >;            /* in zephyr/dts/arm/st/g4/stm32g473.dtsi:65 */
			reg = < 0x40013c00 0x400 >;       /* in zephyr/dts/arm/st/g4/stm32g473.dtsi:66 */
			clocks = < &rcc 0x60 0x8000 >;    /* in zephyr/dts/arm/st/g4/stm32g473.dtsi:67 */
			interrupts = < 0x54 0x5 >;        /* in zephyr/dts/arm/st/g4/stm32g473.dtsi:68 */
			status = "disabled";              /* in zephyr/dts/arm/st/g4/stm32g473.dtsi:69 */
		};

		/* node '/soc/dac@50000c00' defined in zephyr/dts/arm/st/g4/stm32g473.dtsi:72 */
		dac2: dac@50000c00 {
			compatible = "st,stm32-dac";    /* in zephyr/dts/arm/st/g4/stm32g473.dtsi:73 */
			reg = < 0x50000c00 0x400 >;     /* in zephyr/dts/arm/st/g4/stm32g473.dtsi:74 */
			clocks = < &rcc 0x4c 0x20000 >; /* in zephyr/dts/arm/st/g4/stm32g473.dtsi:75 */
			status = "disabled";            /* in zephyr/dts/arm/st/g4/stm32g473.dtsi:76 */
			#io-channel-cells = < 0x1 >;    /* in zephyr/dts/arm/st/g4/stm32g473.dtsi:77 */
		};

		/* node '/soc/dac@50001400' defined in zephyr/dts/arm/st/g4/stm32g473.dtsi:80 */
		dac4: dac@50001400 {
			compatible = "st,stm32-dac";    /* in zephyr/dts/arm/st/g4/stm32g473.dtsi:81 */
			reg = < 0x50001400 0x400 >;     /* in zephyr/dts/arm/st/g4/stm32g473.dtsi:82 */
			clocks = < &rcc 0x4c 0x80000 >; /* in zephyr/dts/arm/st/g4/stm32g473.dtsi:83 */
			status = "disabled";            /* in zephyr/dts/arm/st/g4/stm32g473.dtsi:84 */
			#io-channel-cells = < 0x1 >;    /* in zephyr/dts/arm/st/g4/stm32g473.dtsi:85 */
		};

		/* node '/soc/i2c@40008400' defined in zephyr/dts/arm/st/g4/stm32g473.dtsi:88 */
		i2c4: i2c@40008400 {
			compatible = "st,stm32-i2c-v2"; /* in zephyr/dts/arm/st/g4/stm32g473.dtsi:89 */
			clock-frequency = < 0x186a0 >;  /* in zephyr/dts/arm/st/g4/stm32g473.dtsi:90 */
			#address-cells = < 0x1 >;       /* in zephyr/dts/arm/st/g4/stm32g473.dtsi:91 */
			#size-cells = < 0x0 >;          /* in zephyr/dts/arm/st/g4/stm32g473.dtsi:92 */
			reg = < 0x40008400 0x400 >;     /* in zephyr/dts/arm/st/g4/stm32g473.dtsi:93 */
			clocks = < &rcc 0x5c 0x2 >;     /* in zephyr/dts/arm/st/g4/stm32g473.dtsi:94 */
			interrupts = < 0x52 0x0 >,
			             < 0x53 0x0 >;      /* in zephyr/dts/arm/st/g4/stm32g473.dtsi:95 */
			interrupt-names = "event",
			                  "error";      /* in zephyr/dts/arm/st/g4/stm32g473.dtsi:96 */
			status = "disabled";            /* in zephyr/dts/arm/st/g4/stm32g473.dtsi:97 */
			phandle = < 0x27 >;             /* in zephyr/dts/arm/st/g4/stm32g473.dtsi:116 */
		};

		/* node '/soc/can@40006c00' defined in zephyr/dts/arm/st/g4/stm32g473.dtsi:100 */
		fdcan3: can@40006c00 {
			compatible = "st,stm32-fdcan";                           /* in zephyr/dts/arm/st/g4/stm32g473.dtsi:101 */
			reg = < 0x40006c00 0x400 >,
			      < 0x4000a400 0x9f0 >;                              /* in zephyr/dts/arm/st/g4/stm32g473.dtsi:102 */
			reg-names = "m_can",
			            "message_ram";                               /* in zephyr/dts/arm/st/g4/stm32g473.dtsi:103 */
			interrupts = < 0x58 0x0 >,
			             < 0x59 0x0 >;                               /* in zephyr/dts/arm/st/g4/stm32g473.dtsi:104 */
			interrupt-names = "int0",
			                  "int1";                                /* in zephyr/dts/arm/st/g4/stm32g473.dtsi:105 */
			clocks = < &rcc 0x58 0x2000000 >;                        /* in zephyr/dts/arm/st/g4/stm32g473.dtsi:106 */
			bosch,mram-cfg = < 0x6a0 0x1c 0x8 0x3 0x3 0x0 0x3 0x3 >; /* in zephyr/dts/arm/st/g4/stm32g473.dtsi:107 */
			status = "disabled";                                     /* in zephyr/dts/arm/st/g4/stm32g473.dtsi:108 */
		};
	};

	/* node '/cpus' defined in zephyr/dts/arm/st/g4/stm32g4.dtsi:28 */
	cpus {
		#address-cells = < 0x1 >; /* in zephyr/dts/arm/st/g4/stm32g4.dtsi:29 */
		#size-cells = < 0x0 >;    /* in zephyr/dts/arm/st/g4/stm32g4.dtsi:30 */

		/* node '/cpus/cpu@0' defined in zephyr/dts/arm/st/g4/stm32g4.dtsi:32 */
		cpu0: cpu@0 {
			device_type = "cpu";                  /* in zephyr/dts/arm/st/g4/stm32g4.dtsi:33 */
			compatible = "arm,cortex-m4f";        /* in zephyr/dts/arm/st/g4/stm32g4.dtsi:34 */
			reg = < 0x0 >;                        /* in zephyr/dts/arm/st/g4/stm32g4.dtsi:35 */
			cpu-power-states = < &stop0 &stop1 >; /* in zephyr/dts/arm/st/g4/stm32g4.dtsi:36 */
		};

		/* node '/cpus/power-states' defined in zephyr/dts/arm/st/g4/stm32g4.dtsi:39 */
		power-states {

			/* node '/cpus/power-states/state0' defined in zephyr/dts/arm/st/g4/stm32g4.dtsi:40 */
			stop0: state0 {
				compatible = "zephyr,power-state";    /* in zephyr/dts/arm/st/g4/stm32g4.dtsi:41 */
				power-state-name = "suspend-to-idle"; /* in zephyr/dts/arm/st/g4/stm32g4.dtsi:42 */
				substate-id = < 0x1 >;                /* in zephyr/dts/arm/st/g4/stm32g4.dtsi:43 */
				min-residency-us = < 0x14 >;          /* in zephyr/dts/arm/st/g4/stm32g4.dtsi:44 */
				phandle = < 0x20 >;                   /* in zephyr/dts/arm/st/g4/stm32g4.dtsi:36 */
			};

			/* node '/cpus/power-states/state1' defined in zephyr/dts/arm/st/g4/stm32g4.dtsi:46 */
			stop1: state1 {
				compatible = "zephyr,power-state";    /* in zephyr/dts/arm/st/g4/stm32g4.dtsi:47 */
				power-state-name = "suspend-to-idle"; /* in zephyr/dts/arm/st/g4/stm32g4.dtsi:48 */
				substate-id = < 0x2 >;                /* in zephyr/dts/arm/st/g4/stm32g4.dtsi:49 */
				min-residency-us = < 0x64 >;          /* in zephyr/dts/arm/st/g4/stm32g4.dtsi:50 */
				phandle = < 0x21 >;                   /* in zephyr/dts/arm/st/g4/stm32g4.dtsi:36 */
			};
		};
	};

	/* node '/memory@20000000' defined in zephyr/dts/arm/st/g4/stm32g4.dtsi:55 */
	sram0: memory@20000000 {
		compatible = "mmio-sram";     /* in zephyr/dts/arm/st/g4/stm32g4.dtsi:56 */
		reg = < 0x20000000 0x20000 >; /* in zephyr/dts/arm/st/g4/stm32g474Xe.dtsi:11 */
	};

	/* node '/clocks' defined in zephyr/dts/arm/st/g4/stm32g4.dtsi:59 */
	clocks {

		/* node '/clocks/clk-hse' defined in zephyr/dts/arm/st/g4/stm32g4.dtsi:60 */
		clk_hse: clk-hse {
			#clock-cells = < 0x0 >;            /* in zephyr/dts/arm/st/g4/stm32g4.dtsi:61 */
			compatible = "st,stm32-hse-clock"; /* in zephyr/dts/arm/st/g4/stm32g4.dtsi:62 */
			clock-frequency = < 0x16e3600 >;   /* in zephyr/boards/st/nucleo_g474re/nucleo_g474re.dts:75 */
			status = "okay";                   /* in zephyr/boards/st/nucleo_g474re/nucleo_g474re.dts:76 */
			phandle = < 0x22 >;                /* in zephyr/boards/st/nucleo_g474re/nucleo_g474re.dts:85 */
		};

		/* node '/clocks/clk-hsi' defined in zephyr/dts/arm/st/g4/stm32g4.dtsi:66 */
		clk_hsi: clk-hsi {
			#clock-cells = < 0x0 >;         /* in zephyr/dts/arm/st/g4/stm32g4.dtsi:67 */
			compatible = "fixed-clock";     /* in zephyr/dts/arm/st/g4/stm32g4.dtsi:68 */
			clock-frequency = < 0xf42400 >; /* in zephyr/dts/arm/st/g4/stm32g4.dtsi:69 */
			status = "disabled";            /* in zephyr/dts/arm/st/g4/stm32g4.dtsi:70 */
		};

		/* node '/clocks/clk-hsi48' defined in zephyr/dts/arm/st/g4/stm32g4.dtsi:73 */
		clk_hsi48: clk-hsi48 {
			#clock-cells = < 0x0 >;          /* in zephyr/dts/arm/st/g4/stm32g4.dtsi:74 */
			compatible = "fixed-clock";      /* in zephyr/dts/arm/st/g4/stm32g4.dtsi:75 */
			clock-frequency = < 0x2dc6c00 >; /* in zephyr/dts/arm/st/g4/stm32g4.dtsi:76 */
			status = "okay";                 /* in zephyr/boards/st/nucleo_g474re/nucleo_g474re.dts:71 */
		};

		/* node '/clocks/clk-lse' defined in zephyr/dts/arm/st/g4/stm32g4.dtsi:80 */
		clk_lse: clk-lse {
			#clock-cells = < 0x0 >;            /* in zephyr/dts/arm/st/g4/stm32g4.dtsi:81 */
			compatible = "st,stm32-lse-clock"; /* in zephyr/dts/arm/st/g4/stm32g4.dtsi:82 */
			clock-frequency = < 0x8000 >;      /* in zephyr/dts/arm/st/g4/stm32g4.dtsi:83 */
			driving-capability = < 0x0 >;      /* in zephyr/dts/arm/st/g4/stm32g4.dtsi:84 */
			status = "disabled";               /* in zephyr/dts/arm/st/g4/stm32g4.dtsi:85 */
		};

		/* node '/clocks/clk-lsi' defined in zephyr/dts/arm/st/g4/stm32g4.dtsi:88 */
		clk_lsi: clk-lsi {
			#clock-cells = < 0x0 >;       /* in zephyr/dts/arm/st/g4/stm32g4.dtsi:89 */
			compatible = "fixed-clock";   /* in zephyr/dts/arm/st/g4/stm32g4.dtsi:90 */
			clock-frequency = < 0x7d00 >; /* in zephyr/dts/arm/st/g4/stm32g4.dtsi:91 */
			status = "okay";              /* in zephyr/boards/st/nucleo_g474re/nucleo_g474re.dts:67 */
		};

		/* node '/clocks/pll' defined in zephyr/dts/arm/st/g4/stm32g4.dtsi:95 */
		pll: pll {
			#clock-cells = < 0x0 >;              /* in zephyr/dts/arm/st/g4/stm32g4.dtsi:96 */
			compatible = "st,stm32g4-pll-clock"; /* in zephyr/dts/arm/st/g4/stm32g4.dtsi:97 */
			div-m = < 0x6 >;                     /* in zephyr/boards/st/nucleo_g474re/nucleo_g474re.dts:80 */
			mul-n = < 0x55 >;                    /* in zephyr/boards/st/nucleo_g474re/nucleo_g474re.dts:81 */
			div-p = < 0x7 >;                     /* in zephyr/boards/st/nucleo_g474re/nucleo_g474re.dts:82 */
			div-q = < 0x2 >;                     /* in zephyr/boards/st/nucleo_g474re/nucleo_g474re.dts:83 */
			div-r = < 0x2 >;                     /* in zephyr/boards/st/nucleo_g474re/nucleo_g474re.dts:84 */
			clocks = < &clk_hse >;               /* in zephyr/boards/st/nucleo_g474re/nucleo_g474re.dts:85 */
			status = "okay";                     /* in zephyr/boards/st/nucleo_g474re/nucleo_g474re.dts:86 */
			phandle = < 0x5 >;                   /* in zephyr/boards/st/nucleo_g474re/nucleo_g474re.dts:90 */
		};
	};

	/* node '/dietemp' defined in zephyr/dts/arm/st/g4/stm32g4.dtsi:669 */
	die_temp: dietemp {
		compatible = "st,stm32-temp-cal"; /* in zephyr/dts/arm/st/g4/stm32g4.dtsi:670 */
		ts-cal1-addr = < 0x1fff75a8 >;    /* in zephyr/dts/arm/st/g4/stm32g4.dtsi:671 */
		ts-cal2-addr = < 0x1fff75ca >;    /* in zephyr/dts/arm/st/g4/stm32g4.dtsi:672 */
		ts-cal1-temp = < 0x1e >;          /* in zephyr/dts/arm/st/g4/stm32g4.dtsi:673 */
		ts-cal2-temp = < 0x82 >;          /* in zephyr/dts/arm/st/g4/stm32g4.dtsi:674 */
		ts-cal-vrefanalog = < 0xbb8 >;    /* in zephyr/dts/arm/st/g4/stm32g4.dtsi:675 */
		io-channels = < &adc1 0x10 >;     /* in zephyr/dts/arm/st/g4/stm32g4.dtsi:676 */
		status = "okay";                  /* in zephyr/boards/st/nucleo_g474re/nucleo_g474re.dts:218 */
	};

	/* node '/vref' defined in zephyr/dts/arm/st/g4/stm32g4.dtsi:680 */
	vref: vref {
		compatible = "st,stm32-vref";      /* in zephyr/dts/arm/st/g4/stm32g4.dtsi:681 */
		vrefint-cal-addr = < 0x1fff75aa >; /* in zephyr/dts/arm/st/g4/stm32g4.dtsi:682 */
		vrefint-cal-mv = < 0xbb8 >;        /* in zephyr/dts/arm/st/g4/stm32g4.dtsi:683 */
		io-channels = < &adc1 0x12 >;      /* in zephyr/dts/arm/st/g4/stm32g4.dtsi:684 */
		status = "okay";                   /* in zephyr/boards/st/nucleo_g474re/nucleo_g474re.dts:236 */
	};

	/* node '/vbat' defined in zephyr/dts/arm/st/g4/stm32g4.dtsi:688 */
	vbat: vbat {
		compatible = "st,stm32-vbat"; /* in zephyr/dts/arm/st/g4/stm32g4.dtsi:689 */
		ratio = < 0x3 >;              /* in zephyr/dts/arm/st/g4/stm32g4.dtsi:690 */
		io-channels = < &adc1 0x11 >; /* in zephyr/dts/arm/st/g4/stm32g4.dtsi:691 */
		status = "okay";              /* in zephyr/boards/st/nucleo_g474re/nucleo_g474re.dts:240 */
	};

	/* node '/usbphy' defined in zephyr/dts/arm/st/g4/stm32g4.dtsi:695 */
	usb_fs_phy: usbphy {
		compatible = "usb-nop-xceiv"; /* in zephyr/dts/arm/st/g4/stm32g4.dtsi:696 */
		#phy-cells = < 0x0 >;         /* in zephyr/dts/arm/st/g4/stm32g4.dtsi:697 */
		phandle = < 0x1f >;           /* in zephyr/dts/arm/st/g4/stm32g4.dtsi:626 */
	};

	/* node '/smbus1' defined in zephyr/dts/arm/st/g4/stm32g4.dtsi:700 */
	smbus1: smbus1 {
		compatible = "st,stm32-smbus"; /* in zephyr/dts/arm/st/g4/stm32g4.dtsi:701 */
		#address-cells = < 0x1 >;      /* in zephyr/dts/arm/st/g4/stm32g4.dtsi:702 */
		#size-cells = < 0x0 >;         /* in zephyr/dts/arm/st/g4/stm32g4.dtsi:703 */
		i2c = < &i2c1 >;               /* in zephyr/dts/arm/st/g4/stm32g4.dtsi:704 */
		status = "disabled";           /* in zephyr/dts/arm/st/g4/stm32g4.dtsi:705 */
	};

	/* node '/smbus2' defined in zephyr/dts/arm/st/g4/stm32g4.dtsi:708 */
	smbus2: smbus2 {
		compatible = "st,stm32-smbus"; /* in zephyr/dts/arm/st/g4/stm32g4.dtsi:709 */
		#address-cells = < 0x1 >;      /* in zephyr/dts/arm/st/g4/stm32g4.dtsi:710 */
		#size-cells = < 0x0 >;         /* in zephyr/dts/arm/st/g4/stm32g4.dtsi:711 */
		i2c = < &i2c2 >;               /* in zephyr/dts/arm/st/g4/stm32g4.dtsi:712 */
		status = "disabled";           /* in zephyr/dts/arm/st/g4/stm32g4.dtsi:713 */
	};

	/* node '/smbus3' defined in zephyr/dts/arm/st/g4/stm32g4.dtsi:716 */
	smbus3: smbus3 {
		compatible = "st,stm32-smbus"; /* in zephyr/dts/arm/st/g4/stm32g4.dtsi:717 */
		#address-cells = < 0x1 >;      /* in zephyr/dts/arm/st/g4/stm32g4.dtsi:718 */
		#size-cells = < 0x0 >;         /* in zephyr/dts/arm/st/g4/stm32g4.dtsi:719 */
		i2c = < &i2c3 >;               /* in zephyr/dts/arm/st/g4/stm32g4.dtsi:720 */
		status = "disabled";           /* in zephyr/dts/arm/st/g4/stm32g4.dtsi:721 */
	};

	/* node '/smbus4' defined in zephyr/dts/arm/st/g4/stm32g473.dtsi:112 */
	smbus4: smbus4 {
		compatible = "st,stm32-smbus"; /* in zephyr/dts/arm/st/g4/stm32g473.dtsi:113 */
		#address-cells = < 0x1 >;      /* in zephyr/dts/arm/st/g4/stm32g473.dtsi:114 */
		#size-cells = < 0x0 >;         /* in zephyr/dts/arm/st/g4/stm32g473.dtsi:115 */
		i2c = < &i2c4 >;               /* in zephyr/dts/arm/st/g4/stm32g473.dtsi:116 */
		status = "disabled";           /* in zephyr/dts/arm/st/g4/stm32g473.dtsi:117 */
	};

	/* node '/connector' defined in zephyr/boards/st/nucleo_g474re/arduino_r3_connector.dtsi:8 */
	arduino_header: connector {
		compatible = "arduino-header-r3";          /* in zephyr/boards/st/nucleo_g474re/arduino_r3_connector.dtsi:9 */
		#gpio-cells = < 0x2 >;                     /* in zephyr/boards/st/nucleo_g474re/arduino_r3_connector.dtsi:10 */
		gpio-map-mask = < 0xffffffff 0xffffffc0 >; /* in zephyr/boards/st/nucleo_g474re/arduino_r3_connector.dtsi:11 */
		gpio-map-pass-thru = < 0x0 0x3f >;         /* in zephyr/boards/st/nucleo_g474re/arduino_r3_connector.dtsi:12 */
		gpio-map = < 0x0 0x0 &gpioa 0x0 0x0 >,
		           < 0x1 0x0 &gpioa 0x1 0x0 >,
		           < 0x2 0x0 &gpioa 0x4 0x0 >,
		           < 0x3 0x0 &gpiob 0x0 0x0 >,
		           < 0x4 0x0 &gpioc 0x1 0x0 >,
		           < 0x5 0x0 &gpioc 0x0 0x0 >,
		           < 0x6 0x0 &gpioc 0x5 0x0 >,
		           < 0x7 0x0 &gpioc 0x4 0x0 >,
		           < 0x8 0x0 &gpioa 0xa 0x0 >,
		           < 0x9 0x0 &gpiob 0x3 0x0 >,
		           < 0xa 0x0 &gpiob 0x5 0x0 >,
		           < 0xb 0x0 &gpiob 0x4 0x0 >,
		           < 0xc 0x0 &gpiob 0xa 0x0 >,
		           < 0xd 0x0 &gpioa 0x8 0x0 >,
		           < 0xe 0x0 &gpioa 0x9 0x0 >,
		           < 0xf 0x0 &gpioc 0x7 0x0 >,
		           < 0x10 0x0 &gpiob 0x6 0x0 >,
		           < 0x11 0x0 &gpioa 0x7 0x0 >,
		           < 0x12 0x0 &gpioa 0x6 0x0 >,
		           < 0x13 0x0 &gpioa 0x5 0x0 >,
		           < 0x14 0x0 &gpiob 0x9 0x0 >,
		           < 0x15 0x0 &gpiob 0x8 0x0 >;    /* in zephyr/boards/st/nucleo_g474re/arduino_r3_connector.dtsi:13 */
	};

	/* node '/st-morpho-header' defined in zephyr/boards/st/nucleo_g474re/st_morpho_connector.dtsi:10 */
	st_morpho_header: st-morpho-header {
		compatible = "st-morpho-header";        /* in zephyr/boards/st/nucleo_g474re/st_morpho_connector.dtsi:11 */
		#gpio-cells = < 0x2 >;                  /* in zephyr/boards/st/nucleo_g474re/st_morpho_connector.dtsi:12 */
		gpio-map-mask = < 0xff 0x0 >;           /* in zephyr/boards/st/nucleo_g474re/st_morpho_connector.dtsi:13 */
		gpio-map-pass-thru = < 0x0 0x3f >;      /* in zephyr/boards/st/nucleo_g474re/st_morpho_connector.dtsi:14 */
		gpio-map = < 0x0 0x0 &gpioc 0xa 0x0 >,
		           < 0x1 0x0 &gpioc 0xb 0x0 >,
		           < 0x2 0x0 &gpioc 0xc 0x0 >,
		           < 0x3 0x0 &gpiod 0x2 0x0 >,
		           < 0xc 0x0 &gpioa 0xd 0x0 >,
		           < 0xe 0x0 &gpioa 0xe 0x0 >,
		           < 0x10 0x0 &gpioa 0xf 0x0 >,
		           < 0x14 0x0 &gpiob 0x7 0x0 >,
		           < 0x16 0x0 &gpioc 0xd 0x0 >,
		           < 0x18 0x0 &gpioc 0xe 0x0 >,
		           < 0x1a 0x0 &gpioc 0xf 0x0 >,
		           < 0x1b 0x0 &gpioa 0x0 0x0 >,
		           < 0x1c 0x0 &gpiof 0x0 0x0 >,
		           < 0x1d 0x0 &gpioa 0x1 0x0 >,
		           < 0x1e 0x0 &gpiof 0x1 0x0 >,
		           < 0x1f 0x0 &gpioa 0x4 0x0 >,
		           < 0x21 0x0 &gpiob 0x0 0x0 >,
		           < 0x22 0x0 &gpioc 0x2 0x0 >,
		           < 0x23 0x0 &gpioc 0x1 0x0 >,
		           < 0x24 0x0 &gpioc 0x3 0x0 >,
		           < 0x25 0x0 &gpioc 0x0 0x0 >,
		           < 0x48 0x0 &gpioc 0x9 0x0 >,
		           < 0x49 0x0 &gpioc 0x8 0x0 >,
		           < 0x4a 0x0 &gpiob 0x8 0x0 >,
		           < 0x4b 0x0 &gpioc 0x6 0x0 >,
		           < 0x4c 0x0 &gpiob 0x9 0x0 >,
		           < 0x4d 0x0 &gpioc 0x5 0x0 >,
		           < 0x52 0x0 &gpioa 0x5 0x0 >,
		           < 0x53 0x0 &gpioa 0xc 0x0 >,
		           < 0x54 0x0 &gpioa 0x6 0x0 >,
		           < 0x55 0x0 &gpioa 0xb 0x0 >,
		           < 0x56 0x0 &gpioa 0x7 0x0 >,
		           < 0x57 0x0 &gpiob 0xc 0x0 >,
		           < 0x58 0x0 &gpiob 0x6 0x0 >,
		           < 0x59 0x0 &gpiob 0xb 0x0 >,
		           < 0x5a 0x0 &gpioc 0x7 0x0 >,
		           < 0x5c 0x0 &gpioa 0x9 0x0 >,
		           < 0x5d 0x0 &gpiob 0x2 0x0 >,
		           < 0x5e 0x0 &gpioa 0x8 0x0 >,
		           < 0x5f 0x0 &gpiob 0x1 0x0 >,
		           < 0x60 0x0 &gpiob 0xa 0x0 >,
		           < 0x61 0x0 &gpiob 0xf 0x0 >,
		           < 0x62 0x0 &gpiob 0x4 0x0 >,
		           < 0x63 0x0 &gpiob 0xe 0x0 >,
		           < 0x64 0x0 &gpiob 0x5 0x0 >,
		           < 0x65 0x0 &gpiob 0xd 0x0 >,
		           < 0x66 0x0 &gpiob 0x3 0x0 >,
		           < 0x68 0x0 &gpioa 0xa 0x0 >,
		           < 0x69 0x0 &gpioc 0x4 0x0 >,
		           < 0x6a 0x0 &gpioa 0x2 0x0 >,
		           < 0x6c 0x0 &gpioa 0x3 0x0 >; /* in zephyr/boards/st/nucleo_g474re/st_morpho_connector.dtsi:15 */
	};

	/* node '/leds' defined in zephyr/boards/st/nucleo_g474re/nucleo_g474re.dts:27 */
	leds: leds {
		compatible = "gpio-leds"; /* in zephyr/boards/st/nucleo_g474re/nucleo_g474re.dts:28 */

		/* node '/leds/led_0' defined in zephyr/boards/st/nucleo_g474re/nucleo_g474re.dts:30 */
		green_led: led_0 {
			gpios = < &gpioa 0x5 0x0 >; /* in zephyr/boards/st/nucleo_g474re/nucleo_g474re.dts:31 */
			label = "User LD2";         /* in zephyr/boards/st/nucleo_g474re/nucleo_g474re.dts:32 */
		};
	};

	/* node '/pwmleds' defined in zephyr/boards/st/nucleo_g474re/nucleo_g474re.dts:36 */
	pwmleds {
		compatible = "pwm-leds"; /* in zephyr/boards/st/nucleo_g474re/nucleo_g474re.dts:37 */

		/* node '/pwmleds/green_pwm_led' defined in zephyr/boards/st/nucleo_g474re/nucleo_g474re.dts:39 */
		green_pwm_led: green_pwm_led {
			pwms = < &pwm2 0x1 0x1312d00 0x0 >; /* in zephyr/boards/st/nucleo_g474re/nucleo_g474re.dts:40 */
		};
	};

	/* node '/gpio_keys' defined in zephyr/boards/st/nucleo_g474re/nucleo_g474re.dts:44 */
	gpio_keys {
		compatible = "gpio-keys"; /* in zephyr/boards/st/nucleo_g474re/nucleo_g474re.dts:45 */

		/* node '/gpio_keys/button' defined in zephyr/boards/st/nucleo_g474re/nucleo_g474re.dts:47 */
		user_button: button {
			label = "User";             /* in zephyr/boards/st/nucleo_g474re/nucleo_g474re.dts:48 */
			gpios = < &gpioc 0xd 0x1 >; /* in zephyr/boards/st/nucleo_g474re/nucleo_g474re.dts:49 */
			zephyr,code = < 0xb >;      /* in zephyr/boards/st/nucleo_g474re/nucleo_g474re.dts:50 */
		};
	};
};
